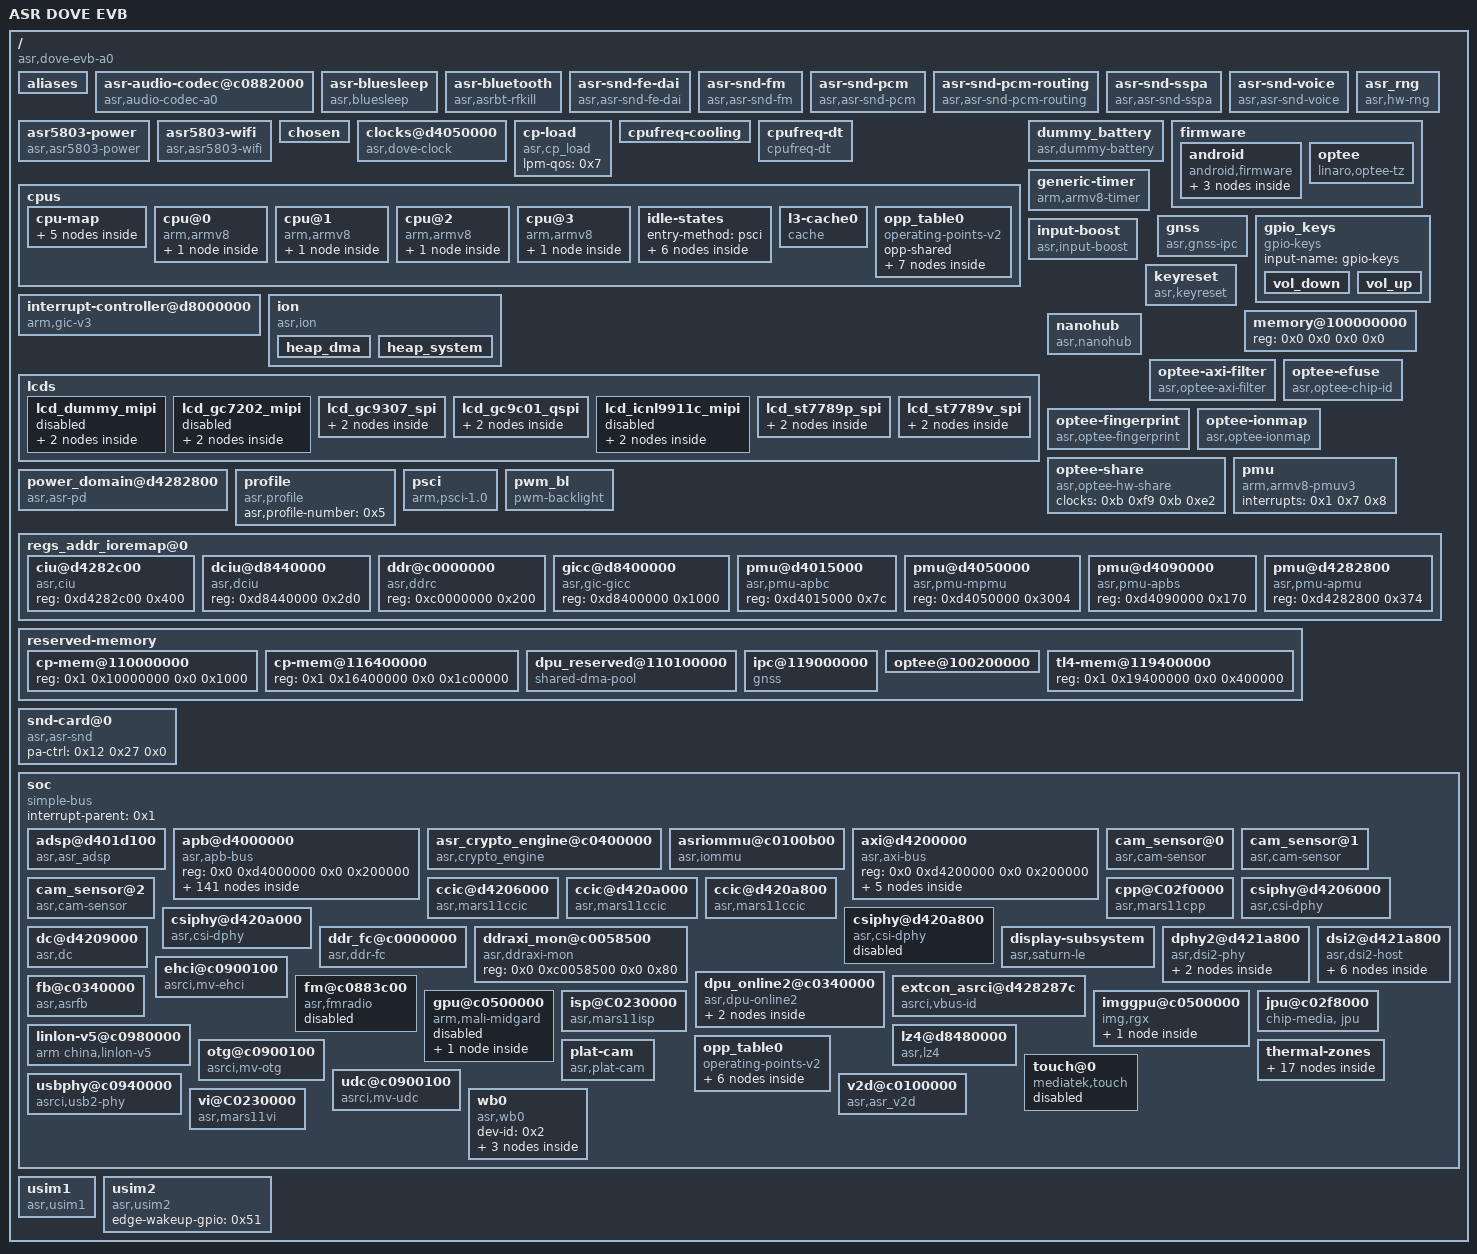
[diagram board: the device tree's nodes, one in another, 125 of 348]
/dts-v1/;

/ {
	#address-cells = <0x2>;
	#size-cells = <0x2>;
	board_id = <0x10000>;
	board_rev = <0x10081>;
	compatible = "asr,dove-evb-a0", "asr,dove";
	interrupt-parent = <0x1>;
	model = "ASR DOVE EVB";

	aliases {
		i2c0 = "/soc/apb@d4000000/i2c@d4011000";
		i2c1 = "/soc/apb@d4000000/i2c@d4010800";
		i2c3 = "/soc/apb@d4000000/i2c@d4018800";
		serial0 = "/soc/apb@d4000000/uart@d4017000";
		serial1 = "/soc/apb@d4000000/uart@d4018000";
		serial2 = "/soc/apb@d4000000/uart@d4017800";
		serial3 = "/soc/apb@d4000000/uart@d4024000";
	};

	asr-audio-codec@c0882000 {
		compatible = "asr,audio-codec-a0", "syscon";
		interrupt-names = "hook_key", "jack_plug";
		interrupts = <0x0 0x6e 0x4 0x0 0x6f 0x4>;
		reg = <0x0 0xc0882000 0x0 0x21c 0x0 0xc088c000 0x0 0x100>;
		reg-names = "codec_ctrl", "aud_pmu";
		status = "ok";
	};

	asr-bluesleep {
		bluetooth-uart = <0x1>;
		bt_ext_wake = <0x12 0x7a 0x0>;
		bt_host_wake = <0x12 0x72 0x0>;
		compatible = "asr,bluesleep";
		status = "ok";
	};

	asr-bluetooth {
		compatible = "asr,asrbt-rfkill";
		status = "ok";
	};

	asr-snd-fe-dai {
		compatible = "asr,asr-snd-fe-dai";
	};

	asr-snd-fm {
		compatible = "asr,asr-snd-fm";
	};

	asr-snd-pcm {
		compatible = "asr,asr-snd-pcm";
	};

	asr-snd-pcm-routing {
		compatible = "asr,asr-snd-pcm-routing";
	};

	asr-snd-sspa {
		compatible = "asr,asr-snd-sspa";
	};

	asr-snd-voice {
		compatible = "asr,asr-snd-voice";
	};

	asr5803-power {
		bt_ldo_en_gpio = <0x73>;
		bt_wifi_reset = <0x12 0x6a 0x0>;
		compatible = "asr,asr5803-power";
		host_wake_bt_gpio = <0x7a>;
		ldo_1v2-supply = <0x30>;
		status = "ok";
		vldo11_wibpa_1v8-supply = <0x4e>;
		wifi_host_wake_wlan = <0x6e>;
		wifi_ldo_en_gpio = <0x6f>;
	};

	asr5803-wifi {
		asr,is_dcs_mode = <0x1>;
		asr,is_dcxo_mode = <0x1>;
		compatible = "asr,asr5803-wifi";
		mac-address = [00 00 00 00 00 00];
		status = "ok";
	};

	asr_rng {
		compatible = "asr,hw-rng";
		status = "ok";
	};

	chosen {
		bootargs = "earlycon clk_ignore_unused log_buf_len=1M cma=16M@0x110400000 uart_dma printk.devkmsg=on";
		stdout-path = "serial0:115200n8";
	};

	clocks@d4050000 {
		#clock-cells = <0x1>;
		asr,keep_dbgclk_on;
		booton-clks = <0x2c 0x46>;
		compatible = "asr,dove-clock";
		interrupts = <0x0 0x60 0x4>;
		phandle = <0xb>;
		reg = <0x0 0xd4050000 0x0 0x209c 0x0 0xd4282800 0x0 0x400 0x0 0xd4015000 0x0 0x1000 0x0 0xd4090000 0x0 0x1000 0x0 0xd4282c00 0x0 0x400 0x0 0xd8440000 0x0 0x98 0x0 0xc0000000 0x0 0x4280>;
		reg-names = "mpmu", "apmu", "apbc", "apbs", "ciu", "dciu", "ddrc";
	};

	cp-load {
		compatible = "asr,cp_load";
		lpm-qos = <0x7>;
		status = "okay";
	};

	cpufreq-cooling {
		status = "ok";
	};

	cpufreq-dt {
		compatible = "cpufreq-dt";
		status = "okay";
	};

	cpus {
		#address-cells = <0x2>;
		#size-cells = <0x0>;

		cpu-map {

			cluster0 {

				core0 {
					cpu = <0x2>;
				};

				core1 {
					cpu = <0x3>;
				};

				core2 {
					cpu = <0x4>;
				};

				core3 {
					cpu = <0x5>;
				};
			};
		};

		cpu@0 {
			#cooling-cells = <0x2>;
			capacity-dmips-mhz = <0x400>;
			clocks = <0xb 0xb6>;
			compatible = "arm,armv8";
			cpu-idle-states = <0x6 0x7 0x8 0x9 0xa>;
			device_type = "cpu";
			dynamic-power-coefficient = <0x78>;
			enable-method = "psci";
			next-level-cache = <0xd>;
			operating-points-v2 = <0xc>;
			phandle = <0x2>;
			reg = <0x0 0x0>;

			l2-cache {
				next-level-cache = <0xe>;
				phandle = <0xd>;
			};
		};

		cpu@1 {
			#cooling-cells = <0x2>;
			capacity-dmips-mhz = <0x400>;
			clocks = <0xb 0xb6>;
			compatible = "arm,armv8";
			cpu-idle-states = <0x6 0x7 0x8 0x9 0xa>;
			device_type = "cpu";
			dynamic-power-coefficient = <0x78>;
			enable-method = "psci";
			next-level-cache = <0xf>;
			operating-points-v2 = <0xc>;
			phandle = <0x3>;
			reg = <0x0 0x100>;

			l2-cache {
				next-level-cache = <0xe>;
				phandle = <0xf>;
			};
		};

		cpu@2 {
			#cooling-cells = <0x2>;
			capacity-dmips-mhz = <0x400>;
			clocks = <0xb 0xb6>;
			compatible = "arm,armv8";
			cpu-idle-states = <0x6 0x7 0x8 0x9 0xa>;
			device_type = "cpu";
			dynamic-power-coefficient = <0x78>;
			enable-method = "psci";
			next-level-cache = <0x10>;
			operating-points-v2 = <0xc>;
			phandle = <0x4>;
			reg = <0x0 0x200>;

			l2-cache {
				next-level-cache = <0xe>;
				phandle = <0x10>;
			};
		};

		cpu@3 {
			#cooling-cells = <0x2>;
			capacity-dmips-mhz = <0x400>;
			clocks = <0xb 0xb6>;
			compatible = "arm,armv8";
			cpu-idle-states = <0x6 0x7 0x8 0x9 0xa>;
			device_type = "cpu";
			dynamic-power-coefficient = <0x78>;
			enable-method = "psci";
			next-level-cache = <0x11>;
			operating-points-v2 = <0xc>;
			phandle = <0x5>;
			reg = <0x0 0x300>;

			l2-cache {
				next-level-cache = <0xe>;
				phandle = <0x11>;
			};
		};

		idle-states {
			entry-method = "psci";

			chip-d1 {
				arm,psci-suspend-param = <0x2010455>;
				compatible = "arm,idle-state";
				entry-latency-us = <0x1f4>;
				exit-latency-us = <0x1f4>;
				local-timer-stop;
				min-residency-us = <0x7d0>;
				phandle = <0x9>;
				wakeup-latency-us = <0x3e8>;
			};

			chip-d1p {
				arm,psci-suspend-param = <0x2010355>;
				compatible = "arm,idle-state";
				entry-latency-us = <0x12c>;
				exit-latency-us = <0x12c>;
				local-timer-stop;
				min-residency-us = <0x4b0>;
				phandle = <0x8>;
				wakeup-latency-us = <0x258>;
			};

			chip-d2 {
				arm,psci-suspend-param = <0x2010555>;
				compatible = "arm,idle-state";
				entry-latency-us = <0x3e8>;
				exit-latency-us = <0x3e8>;
				local-timer-stop;
				min-residency-us = <0xfa0>;
				phandle = <0xa>;
				wakeup-latency-us = <0x7d0>;
			};

			cluster-mp2 {
				arm,psci-suspend-param = <0x1010055>;
				compatible = "arm,idle-state";
				entry-latency-us = <0xf0>;
				exit-latency-us = <0xf0>;
				local-timer-stop;
				min-residency-us = <0x3c0>;
				phandle = <0x7>;
				wakeup-latency-us = <0x1e0>;
			};

			cpu-c1 {
				arm,psci-suspend-param = <0x2>;
				compatible = "arm,idle-state";
				entry-latency-us = <0x19>;
				exit-latency-us = <0x19>;
				min-residency-us = <0x64>;
			};

			cpu-c2 {
				arm,psci-suspend-param = <0x10005>;
				compatible = "arm,idle-state";
				entry-latency-us = <0x5a>;
				exit-latency-us = <0x5a>;
				local-timer-stop;
				min-residency-us = <0x168>;
				phandle = <0x6>;
			};
		};

		l3-cache0 {
			compatible = "cache";
			phandle = <0xe>;
		};

		opp_table0 {
			compatible = "operating-points-v2";
			opp-shared;
			phandle = <0xc>;

			opp1000000000 {
				clock-latency-ns = <0x30d40>;
				opp-hz = <0x0 0x3b9aca00>;
				opp-microvolt = <0x16e360>;
			};

			opp1228000000 {
				clock-latency-ns = <0x30d40>;
				opp-hz = <0x0 0x4931cb00>;
				opp-microvolt = <0x16e360>;
			};

			opp1500000000 {
				clock-latency-ns = <0x30d40>;
				opp-hz = <0x0 0x59682f00>;
				opp-microvolt = <0x16e360>;
			};

			opp409000000 {
				clock-latency-ns = <0x30d40>;
				opp-hz = <0x0 0x1860d840>;
				opp-microvolt = <0xf4240>;
			};

			opp491000000 {
				clock-latency-ns = <0x30d40>;
				opp-hz = <0x0 0x1d4410c0>;
				opp-microvolt = <0xf4240>;
			};

			opp614000000 {
				clock-latency-ns = <0x30d40>;
				opp-hz = <0x0 0x2498e580>;
				opp-microvolt = <0x16e360>;
			};

			opp819000000 {
				clock-latency-ns = <0x30d40>;
				opp-hz = <0x0 0x30d0f2c0>;
				opp-microvolt = <0x16e360>;
			};
		};
	};

	dummy_battery {
		compatible = "asr,dummy-battery";
		status = "okay";
	};

	firmware {

		android {
			compatible = "android,firmware";

			fstab {
				compatible = "android,fstab";

				system {
					compatible = "android,system";
					dev = "/dev/block/platform/soc/d4200000.axi/d4281000.sdh/by-name/system";
					fsmgr_flags = "wait";
					mnt_flags = "ro,barrier=1";
					type = "ext4";
				};

				vendor {
					compatible = "android,vendor";
					dev = "/dev/block/platform/soc/d4200000.axi/d4281000.sdh/by-name/vendor";
					fsmgr_flags = "wait";
					mnt_flags = "ro,barrier=1";
					type = "ext4";
				};
			};
		};

		optee {
			compatible = "linaro,optee-tz";
			interrupts = <0x0 0x7d 0x4>;
			method = "smc";
		};
	};

	generic-timer {
		arm,no-tick-in-suspend;
		clock-frequency = <0x18cba80>;
		compatible = "arm,armv8-timer";
		interrupts = <0x1 0xd 0x8 0x1 0xe 0x8 0x1 0xb 0x8 0x1 0xa 0x8>;
	};

	gnss {
		clock-names = "ap2gnss_clk";
		clocks = <0xb 0x12a>;
		compatible = "asr,gnss-ipc";
		interrupt-names = "gnss_ipc", "gnss_wdt", "gnss_hostwake";
		interrupts = <0x0 0x32 0x4 0x0 0x65 0x4 0x0 0x66 0x4>;
		lna_1v8-supply = <0x49>;
		memory-region = <0x47>;
		reg = <0x0 0xd4282800 0x0 0x3bc 0x0 0xd6200000 0x0 0xfc 0x0 0xd401d200 0x0 0x14 0x0 0xd4015000 0x0 0x9c 0x0 0xd6000000 0x0 0x80000>;
		rf_1v2-supply = <0x30>;
		status = "ok";
		tcxo_1v8-supply = <0x48>;
	};

	gpio_keys {
		compatible = "gpio-keys";
		input-name = "gpio-keys";
		status = "ok";

		vol_down {
			debounce-interval = <0xf>;
			gpios = <0x12 0x3a 0x1>;
			label = "volume_down";
			linux,code = <0x72>;
			linux,input-type = <0x1>;
		};

		vol_up {
			debounce-interval = <0xf>;
			gpios = <0x12 0x39 0x1>;
			label = "volume_up";
			linux,code = <0x73>;
			linux,input-type = <0x1>;
		};
	};

	input-boost {
		compatible = "asr,input-boost";
		status = "okay";
	};

	interrupt-controller@d8000000 {
		#address-cells = <0x2>;
		#interrupt-cells = <0x3>;
		#size-cells = <0x2>;
		compatible = "arm,gic-v3";
		interrupt-controller;
		interrupts = <0x1 0x9 0x8>;
		phandle = <0x1>;
		reg = <0x0 0xd8000000 0x0 0x200000 0x0 0xd8080000 0x0 0x200000>;
	};

	ion {
		compatible = "asr,ion";

		heap_dma {
			heap-id = <0x4>;
			heap-name = "dma";
			heap-type = "ion_dma";
		};

		heap_system {
			heap-id = <0x0>;
			heap-name = "system";
			heap-type = "ion_system";
		};
	};

	keyreset {
		compatible = "asr,keyreset";
		keyreset-need-panic;
		keys-down = <0x74 0x73 0x72>;
		status = "okay";
	};

	lcds {
		status = "ok";

		lcd_dummy_mipi {
			burst-mode = <0x2>;
			dsi-color-format = "rgb888";
			dsi-lane-number = <0x4>;
			dsi-work-mode = <0x1>;
			eotp-enable = <0x0>;
			esd-check-enable = <0x0>;
			fps = <0x3c>;
			hbp = <0x64>;
			height = <0x640>;
			height-mm = <0x7e>;
			hfp = <0x63>;
			hsync = <0x4>;
			lane-number = <0x4>;
			phy-bit-clock = <0xde698>;
			phy-escape-clock = <0xcb20>;
			phy-freq = <0x98580>;
			rgb-mode = <0x3>;
			split-enable = <0x0>;
			status = "disabled";
			use-dcs-write;
			vbp = <0x1c>;
			vfp = <0x8c>;
			vsync = <0x6>;
			width = <0x2d0>;
			width-mm = <0x48>;
			work-mode = <0x0>;

			display-timings {

				timing0 {
					clock-frequency = <0x5dc0000>;
					hactive = <0x2d0>;
					hback-porch = <0x64>;
					hfront-porch = <0x63>;
					hsync-active = <0x1>;
					hsync-len = <0x4>;
					vactive = <0x640>;
					vback-porch = <0x1c>;
					vfront-porch = <0x8c>;
					vsync-active = <0x1>;
					vsync-len = <0x6>;
				};
			};
		};

		lcd_gc7202_mipi {
			backlight = <0x4a>;
			burst-mode = <0x2>;
			dsi-color-format = "rgb888";
			dsi-lane-number = <0x4>;
			dsi-work-mode = <0x1>;
			eotp-enable = <0x0>;
			esd-check-enable = <0x1>;
			esd-check-value = <0x9c>;
			esd-recovery-enable = <0x1>;
			fps = <0x3c>;
			hbp = <0x64>;
			height = <0x640>;
			height-mm = <0x7e>;
			hfp = <0x63>;
			hsync = <0x4>;
			initial-command = [39 01 00 04 ff 55 aa 66 39 01 00 02 ff 20 39 01 00 02 fb 00 39 01 00 02 ff 21 39 01 00 02 fb 00 39 01 00 02 ff 22 39 01 00 02 fb 00 39 01 00 02 ff 23 39 01 00 02 fb 00 39 01 00 02 ff 24 39 01 00 02 fb 00 39 01 00 02 ff 26 39 01 00 02 fb 00 39 01 00 02 ff 27 39 01 00 02 fb 00 39 01 00 02 ff a3 39 01 00 02 fb 00 39 01 00 02 ff b3 39 01 00 02 fb 00 39 01 00 02 ff c3 39 01 00 02 fb 00 39 01 00 02 ff 22 39 01 00 02 e4 01 39 01 00 02 01 06 39 01 00 02 02 40 39 01 00 02 25 08 39 01 00 02 26 00 39 01 00 02 2e 6f 39 01 00 02 2f 00 39 01 00 02 36 09 39 01 00 02 37 00 39 01 00 02 3f 6f 39 01 00 02 40 00 39 01 00 02 0e 33 39 01 00 02 dc 00 39 01 00 02 08 40 39 01 00 02 ff 21 39 01 00 02 01 25 39 01 00 02 02 05 39 01 00 02 03 1a 39 01 00 02 04 25 39 01 00 02 05 25 39 01 00 02 06 01 39 01 00 02 07 0f 39 01 00 02 08 0d 39 01 00 02 09 0b 39 01 00 02 0a 09 39 01 00 02 0b 23 39 01 00 02 0c 23 39 01 00 02 0d 25 39 01 00 02 0e 25 39 01 00 02 0f 25 39 01 00 02 10 25 39 01 00 02 11 25 39 01 00 02 12 25 39 01 00 02 13 25 39 01 00 02 14 25 39 01 00 02 15 25 39 01 00 02 16 25 39 01 00 02 17 25 39 01 00 02 18 04 39 01 00 02 19 1a 39 01 00 02 1a 25 39 01 00 02 1b 25 39 01 00 02 1c 00 39 01 00 02 1d 0e 39 01 00 02 1e 0c 39 01 00 02 1f 0a 39 01 00 02 20 08 39 01 00 02 21 23 39 01 00 02 22 23 39 01 00 02 23 25 39 01 00 02 24 25 39 01 00 02 25 25 39 01 00 02 26 25 39 01 00 02 27 25 39 01 00 02 28 25 39 01 00 02 29 25 39 01 00 02 2a 25 39 01 00 02 2b 25 39 01 00 02 2d 25 39 01 00 02 45 33 39 01 00 02 7e 03 39 01 00 02 c2 85 39 01 00 02 7f 21 39 01 00 02 8b 21 39 01 00 02 80 01 39 01 00 02 8c 1a 39 01 00 02 81 1a 39 01 00 02 8d 01 39 01 00 02 af 40 39 01 00 02 b0 40 39 01 00 02 83 04 39 01 00 02 8f 04 39 01 00 02 84 55 39 01 00 02 90 55 39 01 00 02 85 55 39 01 00 02 91 55 39 01 00 02 87 00 39 01 00 02 93 00 39 01 00 02 2e 00 39 01 00 02 88 a7 39 01 00 02 89 20 39 01 00 02 8a 33 39 01 00 02 94 a7 39 01 00 02 95 20 39 01 00 02 96 33 39 01 00 02 46 53 39 01 00 02 4c 53 39 01 00 02 5e 41 39 01 00 02 64 41 39 01 00 02 82 50 39 01 00 02 8e 50 39 01 00 02 47 02 39 01 00 02 4d 01 39 01 00 02 48 01 39 01 00 02 4e 02 39 01 00 02 5f 21 39 01 00 02 65 22 39 01 00 02 60 22 39 01 00 02 66 21 39 01 00 02 76 40 39 01 00 02 77 40 39 01 00 02 7a 44 39 01 00 02 7b 44 39 01 00 02 49 55 39 01 00 02 4a 55 39 01 00 02 4f 55 39 01 00 02 50 55 39 01 00 02 61 55 39 01 00 02 62 55 39 01 00 02 67 55 39 01 00 02 68 55 39 01 00 02 c6 56 39 01 00 02 d1 13 39 01 00 02 ff b3 39 01 00 02 4a 00 39 01 00 02 7d 28 39 01 00 02 5b 00 39 01 00 02 48 23 39 01 00 02 7c 88 39 01 00 02 3e 03 39 01 00 02 3f 7f 39 01 00 02 5e 10 39 01 00 02 58 84 39 01 00 02 ff 20 39 01 00 02 29 01 39 01 00 02 2d 1f 39 01 00 02 02 27 39 01 00 02 03 27 39 01 00 02 04 45 39 01 00 02 05 45 39 01 00 02 0a 1b 39 01 00 02 0b 1b 39 01 00 02 0c 4b 39 01 00 02 0d 4b 39 01 00 02 1c 28 39 01 00 02 1d 28 39 01 00 02 77 74 39 01 00 02 78 74 39 01 00 02 a5 00 39 01 00 02 a6 ff 39 01 00 02 a9 00 39 01 00 02 aa ff 39 01 00 02 ad 00 39 01 00 02 ae ff 39 01 00 02 b1 00 39 01 00 02 b2 ff 39 01 00 02 c3 00 39 01 00 02 c4 5f 39 01 00 02 c5 00 39 01 00 02 c6 5f 39 01 00 02 b3 00 39 01 00 02 b4 20 39 01 00 02 b5 00 39 01 00 02 b6 dc 39 01 00 02 c7 00 39 01 00 02 c8 93 39 01 00 02 c9 00 39 01 00 02 ca 93 39 01 00 02 b7 00 39 01 00 02 b8 20 39 01 00 02 b9 01 39 01 00 02 ba 90 39 01 00 02 cb 00 39 01 00 02 cc 90 39 01 00 02 bb 00 39 01 00 02 bc 16 39 01 00 02 bd 00 39 01 00 02 be 12 39 01 00 02 d5 0e 39 01 00 02 7e 01 39 01 00 02 7f 00 39 01 00 02 80 01 39 01 00 02 81 00 39 01 00 02 82 00 39 01 00 02 83 04 39 01 00 02 84 04 39 01 00 02 85 01 39 01 00 02 86 8b 39 01 00 02 87 01 39 01 00 02 88 8b 39 01 00 02 8a 03 39 01 00 02 8b 03 39 01 00 02 18 44 39 01 00 02 17 51 39 01 00 02 12 a2 39 01 00 02 15 4c 39 01 00 02 a3 44 39 01 00 02 a7 44 39 01 00 02 d3 03 39 01 00 02 24 99 39 01 00 02 25 06 39 01 00 02 ff 23 39 01 00 11 01 00 00 00 14 00 53 00 7e 00 95 00 b0 00 be 00 d0 39 01 00 11 02 00 e0 01 0e 01 32 01 61 01 80 01 b4 01 dd 01 de 39 01 00 11 03 02 0a 02 44 02 6b 02 a0 02 c4 02 f6 03 06 03 18 39 01 00 0d 04 03 2b 03 44 03 62 03 88 03 c5 03 ff 39 01 00 11 05 00 00 00 14 00 53 00 7e 00 95 00 b0 00 be 00 d0 39 01 00 11 06 00 e0 01 0e 01 32 01 61 01 80 01 b4 01 dd 01 de 39 01 00 11 07 02 0a 02 44 02 6b 02 a0 02 c4 02 f6 03 06 03 18 39 01 00 0d 08 03 2b 03 44 03 62 03 88 03 c5 03 ff 39 01 00 11 09 00 00 00 14 00 53 00 7e 00 95 00 b0 00 be 00 d0 39 01 00 11 0a 00 e0 01 0e 01 32 01 61 01 80 01 b4 01 dd 01 de 39 01 00 11 0b 02 0a 02 44 02 6b 02 a0 02 c4 02 f6 03 06 03 18 39 01 00 0d 0c 03 2b 03 44 03 62 03 88 03 c5 03 ff 39 01 00 11 0d 00 00 00 14 00 53 00 7e 00 95 00 b0 00 be 00 d0 39 01 00 11 0e 00 e0 01 0e 01 32 01 61 01 80 01 b4 01 dd 01 de 39 01 00 11 0f 02 0a 02 44 02 6b 02 a0 02 c4 02 f6 03 06 03 18 39 01 00 0d 10 03 2b 03 44 03 62 03 88 03 c5 03 ff 39 01 00 11 11 00 00 00 14 00 53 00 7e 00 95 00 b0 00 be 00 d0 39 01 00 11 12 00 e0 01 0e 01 32 01 61 01 80 01 b4 01 dd 01 de 39 01 00 11 13 02 0a 02 44 02 6b 02 a0 02 c4 02 f6 03 06 03 18 39 01 00 0d 14 03 2b 03 44 03 62 03 88 03 c5 03 ff 39 01 00 11 15 00 00 00 14 00 53 00 7e 00 95 00 b0 00 be 00 d0 39 01 00 11 16 00 e0 01 0e 01 32 01 61 01 80 01 b4 01 dd 01 de 39 01 00 11 17 02 0a 02 44 02 6b 02 a0 02 c4 02 f6 03 06 03 18 39 01 00 0d 18 03 2b 03 44 03 62 03 88 03 c5 03 ff 39 01 00 02 b9 31 39 01 00 02 b8 b7 39 01 00 02 35 16 39 01 00 02 36 0c 39 01 00 02 30 00 39 01 00 11 1f 0a 00 20 00 44 00 70 00 a8 00 e6 00 0a 00 20 00 39 01 00 09 20 44 00 70 00 a8 00 ff 00 39 01 00 11 21 a7 00 b2 00 c0 00 cd 00 da 00 f3 00 d4 00 e4 00 39 01 00 09 22 ec 00 f1 00 f1 00 ff 00 39 01 00 11 23 00 00 00 00 00 00 00 00 00 00 00 00 00 00 00 00 39 01 00 09 24 00 00 00 00 00 00 00 00 39 01 00 02 ff 20 39 01 00 02 50 00 39 01 00 02 51 22 39 01 00 02 ff 26 39 01 00 05 1d 0c 00 00 00 39 01 00 02 ff a3 39 01 00 02 fa 01 39 01 00 02 35 00 39 01 00 02 45 10 39 01 00 02 05 05 39 01 00 02 2b fb 39 01 00 02 ff 10 39 01 00 02 36 08 39 01 00 02 69 00 39 01 00 02 35 00 39 01 00 02 ff b3 39 01 78 02 51 11 39 01 00 02 ff 10 39 01 78 02 11 00 39 01 14 02 29 00];
			lane-number = <0x4>;
			phy-bit-clock = <0xde698>;
			phy-escape-clock = <0xcb20>;
			phy-freq = <0x98580>;
			read-id-command = [37 01 00 01 01 14 01 00 01 04];
			rgb-mode = <0x3>;
			sleep-in-command = [39 01 00 04 ff 55 aa 66 39 01 00 02 ff 20 39 01 00 02 4a 01 39 01 00 02 48 10 39 01 00 02 49 00 39 01 00 02 ff 21 39 01 00 02 d1 00 39 01 00 02 ff 10 05 01 14 01 28 39 01 00 02 ff b3 39 01 32 02 61 be 39 01 00 02 ff 10 05 01 78 01 10 39 01 00 02 ff b3 39 01 32 02 61 00 39 01 00 04 ff 55 aa 66 39 01 00 02 ff 26 39 01 00 02 fb 00 39 01 00 05 1d a2 aa aa 0a 39 01 00 02 ff 10 39 01 00 02 fb 00 39 01 0a 02 4f 01];
			sleep-out-command = [05 01 78 01 11 05 01 14 01 29];
			split-enable = <0x0>;
			status = "disabled";
			use-dcs-write;
			vbp = <0x1c>;
			vfp = <0x8c>;
			vsync = <0x6>;
			width = <0x2d0>;
			width-mm = <0x48>;
			work-mode = <0x0>;

			display-timings {

				timing0 {
					clock-frequency = <0x5dc0000>;
					hactive = <0x2d0>;
					hback-porch = <0x64>;
					hfront-porch = <0x63>;
					hsync-active = <0x1>;
					hsync-len = <0x4>;
					vactive = <0x640>;
					vback-porch = <0x1c>;
					vfront-porch = <0x8c>;
					vsync-active = <0x1>;
					vsync-len = <0x6>;
				};
			};
		};

		lcd_gc9307_spi {
			bg-color = <0xff>;
			cmd-initial-0 = [00 01 fe 00 00 01 ef 00 00 01 36 01 48 00 01 3a 01 05 00 01 86 01 98 00 01 89 01 03 00 01 8b 01 80 00 01 8d 01 22 00 01 8e 01 0f 00 01 e8 02 10 40 00 01 ff 01 62 00 01 99 01 3e 00 01 9d 01 4b 00 01 c3 01 34 00 01 c4 01 34 00 01 c9 01 2a 00 01 f0 06 87 08 09 08 06 29 00 01 f2 06 87 08 09 08 06 29 00 01 f1 06 c0 89 6a 3c fe 3f 00 01 f3 06 c0 89 6a 3c fe 3f 00 01 35 01 00 00 01 44 02 00 0a 78 01 11 00 00 01 29 00 14 01 2c 00];
			cmd-initial-1 = [00 01 fe 00 00 01 ef 00 00 01 36 01 48 00 01 3a 01 05 00 01 86 01 98 00 01 89 01 03 00 01 8b 01 80 00 01 8d 01 22 00 01 8e 01 0f 00 01 e8 02 20 40 00 01 ff 01 62 00 01 99 01 3e 00 01 9d 01 4b 00 01 c3 01 34 00 01 c4 01 34 00 01 c9 01 2a 00 01 f0 06 87 08 09 08 06 29 00 01 f2 06 87 08 09 08 06 29 00 01 f1 06 c0 89 6a 3c fe 3f 00 01 f3 06 c0 89 6a 3c fe 3f 00 01 35 01 00 00 01 44 02 00 1a 78 01 11 00 00 01 29 00 14 01 2c 00];
			cmd-initial-2 = [00 01 fe 00 00 01 ef 00 00 01 36 01 48 00 01 35 01 00 00 01 3a 01 05 00 01 86 01 98 00 01 89 01 13 00 01 8b 01 80 00 01 8d 01 33 00 01 8e 01 0f 00 01 ec 03 33 07 af 00 01 c9 01 05 00 01 e8 02 13 17 00 01 c3 01 10 00 01 c4 01 10 00 01 ff 01 62 00 01 99 01 3e 00 01 9d 01 4b 00 01 98 01 3e 00 01 9c 01 4b 00 01 f0 06 c7 08 08 08 05 2e 00 01 f2 06 c7 08 08 08 05 2e 00 01 f1 06 45 8f 6f 33 36 4f 00 01 f3 06 45 8f 6f 33 36 4f 00 01 44 02 00 0a 78 01 11 00 00 01 29 00 14 01 2c 00];
			cmd-initial-3 = [00 01 fe 00 00 01 ef 00 00 01 36 01 48 00 01 35 01 00 00 01 3a 01 05 00 01 86 01 98 00 01 89 01 33 00 01 8b 01 80 00 01 8d 01 33 00 01 8e 01 0f 00 01 ec 03 33 0c d1 00 01 c9 01 16 00 01 e8 02 12 00 00 01 c3 01 14 00 01 c4 01 08 00 01 ff 01 62 00 01 99 01 3e 00 01 9d 01 4b 00 01 98 01 3e 00 01 9c 01 4b 00 01 f0 06 c3 05 08 07 04 26 00 01 f2 06 c3 05 08 07 04 26 00 01 f1 06 3f 7f 6f 35 36 4f 00 01 f3 06 3f 7f 6f 35 36 4f 00 01 44 02 00 0a 78 01 11 00 00 01 29 00 14 01 2c 00];
			cmd-initial-4 = [00 01 fe 00 00 01 ef 00 00 01 36 01 48 00 01 3a 01 05 00 01 35 01 00 00 01 86 01 98 00 01 89 01 13 00 01 8b 01 80 00 01 8d 01 33 00 01 8e 01 0f 00 01 ec 03 33 07 af 00 01 c9 01 05 00 01 e8 02 13 17 00 01 c3 01 10 00 01 c4 01 10 00 01 ff 01 62 00 01 99 01 3e 00 01 9d 01 4b 00 01 98 01 3e 00 01 9c 01 4b 00 01 f0 06 c7 08 08 08 05 2e 00 01 f1 06 45 8f 6f 33 36 4f 00 01 f2 06 c7 08 08 08 05 2e 00 01 f3 06 45 8f 6f 33 36 4f 00 01 44 02 00 0a 78 01 11 00 00 01 29 00 00 01 2c 00];
			cmd-initial-5 = [00 01 fe 00 00 01 ef 00 00 01 36 01 48 00 01 3a 01 05 00 01 86 01 98 00 01 89 01 03 00 01 8b 01 80 00 01 8d 01 22 00 01 8e 01 0f 00 01 e8 02 12 00 00 01 c3 01 47 00 01 c4 01 28 00 01 c9 01 08 00 01 ff 01 62 00 01 99 01 3e 00 01 9d 01 4b 00 01 f0 06 07 0b 0c 0a 06 31 00 01 f2 06 07 07 04 06 06 21 00 01 f1 06 4a 78 76 33 2f af 00 01 f3 06 38 74 72 22 28 6f 00 01 35 01 00 00 01 44 02 00 0a 00 01 11 00 00 01 29 00 00 01 2c 00];
			cmd-initial-6 = [00 01 fe 00 00 01 ef 00 00 01 36 01 48 00 01 3a 01 05 00 01 86 01 98 00 01 89 01 33 00 01 8b 01 80 00 01 8d 01 33 00 01 8e 01 0f 00 01 ec 03 33 0c d1 00 01 c9 01 16 00 01 e8 02 13 17 00 01 c3 01 22 00 01 c4 01 16 00 01 ff 01 62 00 01 99 01 3e 00 01 9d 01 4b 00 01 98 01 3e 00 01 9c 01 4b 00 01 f0 06 c3 05 08 07 04 26 00 01 f2 06 c3 05 08 07 04 26 00 01 f1 06 3f 7f 6f 35 36 4f 00 01 f3 06 3f 7f 6f 35 36 4f 00 01 35 01 00 00 01 44 02 00 0a 78 01 11 00 00 01 29 00 14 01 2c 00];
			cmd-initial-7 = [00 01 fe 00 00 01 ef 00 00 01 36 01 48 00 01 3a 01 05 00 01 86 01 98 00 01 89 01 33 00 01 8b 01 80 00 01 8d 01 33 00 01 8e 01 0f 00 01 ec 03 33 0c d1 00 01 c9 01 16 00 01 e8 02 13 17 00 01 c3 01 22 00 01 c4 01 16 00 01 ff 01 62 00 01 99 01 3e 00 01 9d 01 4b 00 01 98 01 3e 00 01 9c 01 4b 00 01 f0 06 c3 05 08 07 04 26 00 01 f2 06 c3 05 08 07 04 26 00 01 f1 06 3f 7f 6f 35 36 4f 00 01 f3 06 3f 7f 6f 35 36 4f 00 01 35 01 00 00 01 44 02 00 0a 78 01 11 00 00 01 29 00 14 01 2c 00];
			cmd-read-id = [00 01 da 01 00 00 01 db 01 93 00 01 dc 01 07 00 01 04 03 07 93 00];
			cmd-set-window-240x240 = <0x12a04 0xef 0x12b04 0xef 0x12c00>;
			cmd-set-window-240x280 = <0x12a04 0xef 0x12b04 0x13012b 0x12c00>;
			cmd-set-window-240x284 = <0x12a04 0xef 0x12b04 0x11b 0x12c00>;
			cmd-set-window-240x296 = <0x12a04 0xef 0x12b04 0x127 0x12c00>;
			cmd-set-window-240x320 = <0x12a04 0xef 0x12b04 0x13f 0x12c00>;
			cmd-sleep-in = <0x14012800 0x78011000>;
			cmd-sleep-out = <0x78011100 0x78012900>;
			custom-cmd-set-window = <0x0>;
			data-lane-number = <0x1>;
			device-id = <0x0>;
			endian = <0x1>;
			format = "rgb565";
			frame-sync;
			height-mm = <0x7e>;
			interface-id = <0x1>;
			line-number = <0x4>;
			mclk-freq = <0x124f8000>;
			non-block;
			reset-sequence = <0x140178>;
			sample-edge = <0x0>;
			spi-rclk-freq = <0x177000>;
			spi-wclk-freq = <0x3197500>;
			te-en = <0x1>;
			te-polarity = <0x0>;
			width-mm = <0x48>;

			display-timings {

				timing0 {
					clock-frequency = <0x4a6214>;
					hactive = <0xf0>;
					hback-porch = <0x64>;
					hfront-porch = <0x63>;
					hsync-active = <0x1>;
					hsync-len = <0x4>;
					vactive = <0xf0>;
					vback-porch = <0x8>;
					vfront-porch = <0x8>;
					vsync-active = <0x1>;
					vsync-len = <0x6>;
				};
			};
		};

		lcd_gc9c01_qspi {
			bg-color = <0xff>;
			cmd-initial = [00 04 02 00 fe 00 00 00 04 02 00 ef 00 00 00 04 02 00 80 00 01 11 00 04 02 00 81 00 01 70 00 04 02 00 82 00 01 09 00 04 02 00 83 00 01 03 00 04 02 00 84 00 01 20 00 04 02 00 89 00 01 10 00 04 02 00 8a 00 01 4f 00 04 02 00 8b 00 01 08 00 04 02 00 8c 00 01 59 00 04 02 00 8d 00 01 51 00 04 02 00 36 00 01 00 00 04 02 00 3a 00 01 05 00 04 02 00 ec 00 01 77 00 04 02 00 74 00 06 01 80 00 00 00 00 00 04 02 00 98 00 01 3e 00 04 02 00 99 00 01 3e 00 04 02 00 c3 00 01 3a 00 04 02 00 c4 00 01 16 00 04 02 00 a1 00 02 01 04 00 04 02 00 a2 00 02 01 04 00 04 02 00 cb 00 01 02 00 04 02 00 7c 00 02 b6 26 00 04 02 00 ac 00 01 24 00 04 02 00 f6 00 01 80 00 04 02 00 b5 00 02 09 09 00 04 02 00 60 00 04 38 0b 5b 56 00 04 02 00 63 00 04 3a e0 5b 56 00 04 02 00 64 00 06 38 0d 72 dd 5b 56 00 04 02 00 66 00 06 38 11 72 e1 5b 56 00 04 02 00 68 00 07 3b 08 08 00 08 29 5b 00 04 02 00 6e 00 20 00 00 00 07 01 13 11 0b 09 16 15 1d 1e 00 00 00 00 00 00 1e 1d 15 16 0a 0c 12 14 02 08 00 00 00 00 04 02 00 be 00 01 11 00 04 02 00 6c 00 07 cc 0c cc 84 cc 04 50 00 04 02 00 7d 00 01 72 00 04 02 00 7e 00 01 38 00 04 02 00 70 00 0a 02 03 09 05 0c 06 09 05 0c 06 00 04 02 00 90 00 04 06 06 05 06 00 04 02 00 93 00 03 45 ff 00 00 04 02 00 f0 00 06 46 0b 0f 0a 10 3f 00 04 02 00 f1 00 06 52 9a 4f 36 37 ff 00 04 02 00 f2 00 06 46 0b 0f 0a 10 3f 00 04 02 00 f3 00 06 52 9a 4f 36 37 ff 00 04 02 00 35 00 01 00 00 04 02 00 44 00 02 00 25 00 04 02 00 b4 00 02 0a 50 00 04 02 00 fb 00 02 00 00 78 04 02 00 11 00 00 14 04 02 00 29 00 00];
			cmd-set-window = [00 04 02 00 2a 00 04 00 00 01 67 00 04 02 00 2b 00 04 00 00 01 67];
			cmd-sleep-in = [78 04 02 00 28 00 00 96 04 02 00 10 00 00];
			cmd-sleep-out = [78 04 02 00 11 00 00 64 04 02 00 29 00 00];
			cmd-start = [00 04 32 00 2c 00 00];
			data-lane-number = <0x1>;
			device-id = <0x0>;
			endian = <0x1>;
			format = "rgb565";
			frame-sync;
			height-mm = <0x7e>;
			interface-id = <0x1>;
			line-number = <0x4>;
			mclk-freq = <0x124f8000>;
			qspi;
			reset-sequence = [01 78 00 64 01 78];
			sample-edge = <0x0>;
			spi-rclk-freq = <0x177000>;
			spi-wclk-freq = <0x30d4000>;
			te-en = <0x0>;
			te-polarity = <0x0>;
			width-mm = <0x48>;

			display-timings {

				timing0 {
					clock-frequency = <0x3197500>;
					hactive = <0x168>;
					hback-porch = <0x64>;
					hfront-porch = <0x63>;
					hsync-active = <0x1>;
					hsync-len = <0x4>;
					vactive = <0x168>;
					vback-porch = <0x8>;
					vfront-porch = <0x8>;
					vsync-active = <0x1>;
					vsync-len = <0x6>;
				};
			};
		};

		lcd_icnl9911c_mipi {
			backlight = <0x4a>;
			burst-mode = <0x2>;
			dsi-color-format = "rgb888";
			dsi-lane-number = <0x4>;
			dsi-work-mode = <0x1>;
			eotp-enable = <0x0>;
			esd-check-enable = <0x1>;
			esd-check-value = <0x1c>;
			esd-recovery-enable = <0x1>;
			fps = <0x3c>;
			hbp = <0x60>;
			height = <0x640>;
			height-mm = <0x7e>;
			hfp = <0x61>;
			hsync = <0x4>;
			initial-command = [39 01 00 04 df 93 83 16 39 01 00 02 de 00 39 01 00 13 b3 10 80 85 00 ff ff 00 00 00 00 64 64 3c 3c 33 11 50 50 39 01 00 06 b2 01 23 60 88 24 39 01 00 04 b6 0c 99 ae 39 01 00 04 b9 3c 33 35 39 01 00 08 bb 0c 31 43 64 3c 20 20 39 01 00 03 bd 00 6c 39 01 00 06 c0 00 d5 00 d5 00 39 01 00 2b cb 5e 4d 40 2f 22 1e 11 19 07 27 2b 30 52 42 4d 41 3e 33 23 17 02 5e 4d 40 2f 22 1e 11 19 07 27 2b 30 52 42 4d 41 3e 33 23 17 02 39 01 00 02 cc 33 39 01 00 03 cd 10 10 39 01 00 05 bf 50 32 33 c3 39 01 00 0e c3 13 00 06 16 9b 00 9d 08 16 04 18 08 16 39 01 00 0b c5 30 20 87 00 00 00 00 38 00 11 39 01 00 05 c6 00 b6 d2 14 39 01 00 11 ce 01 00 00 00 00 00 3c 3c 3c 3c 3c 3c 3c 3c 3c 3c 39 01 00 11 cf 00 00 00 00 00 00 c0 c0 c0 c0 c0 c0 c0 c0 c0 c0 39 01 00 1e d0 00 1f 1f 1f 1f 1f 1e 1f 17 18 04 06 08 0a 00 10 1f 1f 1f 1f 1f 1f 1f 00 00 00 03 c0 00 39 01 00 1e d1 00 1f 1f 1f 1f 1f 1e 1f 17 18 05 07 09 0b 01 11 1f 1f 1f 1f 1f 1f 1f 00 00 00 03 c0 00 39 01 00 1e d2 00 1f 1f 1f 1f 1f 1f 1e 17 18 0b 09 07 05 11 01 1f 1f 1f 1f 1f 1f 1f 00 00 00 03 c0 00 39 01 00 1e d3 00 1f 1f 1f 1f 1f 1f 1e 17 18 0a 08 06 04 10 00 1f 1f 1f 1f 1f 1f 1f 00 00 00 03 c0 00 39 01 00 3f d4 10 00 00 10 00 0d 00 00 00 00 00 03 04 00 10 a6 54 00 04 03 03 00 01 00 04 01 01 11 60 03 00 05 01 01 00 00 04 00 0a 06 61 00 0f 00 00 00 00 00 00 00 00 00 00 00 00 00 00 00 00 81 03 d4 39 01 00 1c d5 03 10 03 00 01 00 00 00 00 43 00 00 00 07 32 5a 00 4a 3b 00 00 1e 02 73 00 12 00 39 01 00 14 d7 00 69 79 69 79 69 79 69 79 69 79 2f 79 69 79 69 79 69 79 39 01 00 02 de 01 39 01 00 02 b5 6f 39 01 00 03 c5 22 12 39 01 00 08 c6 3f 0c 00 00 01 e0 78 39 01 00 02 de 02 39 01 00 06 b3 20 a0 ea 5f 4b 39 01 00 09 b7 44 00 88 00 03 00 6e 10 39 01 00 02 bd 14 39 01 00 09 c1 00 40 20 00 14 14 14 14 39 01 00 08 c2 42 70 01 01 e0 73 f8 39 01 00 07 c3 20 fb 00 a0 20 62 39 01 00 0b e5 00 e6 e5 02 27 42 27 42 09 00 39 01 00 04 e6 10 10 bd 39 01 00 04 ec 01 7f 22 39 01 00 02 de 03 39 01 00 02 d1 00 39 01 00 02 de 00 39 01 1e 02 35 00 39 01 78 02 11 00 39 01 78 02 29 00];
			lane-number = <0x4>;
			phy-bit-clock = <0xde698>;
			phy-escape-clock = <0xcb20>;
			phy-freq = <0x98580>;
			read-id-command = [37 01 00 01 01 14 01 00 01 04];
			rgb-mode = <0x3>;
			sleep-in-command = [39 01 78 01 28 39 01 78 01 10];
			sleep-out-command = [05 01 78 01 11 05 01 14 01 29];
			split-enable = <0x0>;
			status = "disabled";
			use-dcs-write;
			vbp = <0x20>;
			vfp = <0x96>;
			vsync = <0x4>;
			width = <0x2d0>;
			width-mm = <0x48>;
			work-mode = <0x0>;

			display-timings {

				timing0 {
					clock-frequency = <0x5dc0000>;
					hactive = <0x2d0>;
					hback-porch = <0x60>;
					hfront-porch = <0x61>;
					hsync-active = <0x1>;
					hsync-len = <0x4>;
					vactive = <0x640>;
					vback-porch = <0x20>;
					vfront-porch = <0x96>;
					vsync-active = <0x1>;
					vsync-len = <0x4>;
				};
			};
		};

		lcd_st7789p_spi {
			bg-color = <0xff>;
			cmd-initial = [78 01 11 00 78 01 36 01 00 00 01 b0 02 00 d0 00 01 3a 01 05 00 01 b2 05 07 07 00 33 33 00 01 b7 01 35 00 01 bb 01 20 00 01 c0 01 2c 00 01 c2 01 01 00 01 c3 01 13 00 01 c6 01 13 00 01 d0 02 a7 a1 00 01 d0 02 a4 a1 00 01 d6 01 a1 00 01 e0 0e f0 03 08 07 06 13 2b 33 41 36 12 12 28 30 00 01 e1 0e f0 05 0a 09 08 05 2b 32 40 37 14 14 29 31 00 01 35 01 00 00 01 44 02 00 0e 00 01 21 00 00 01 29 00];
			cmd-read-id = [00 01 da 01 81 00 01 db 01 81 00 01 dc 01 b3 00 01 04 03 b3 81 81];
			cmd-set-window = <0x12a04 0xef 0x12b04 0x127 0x12c00>;
			cmd-sleep-in = <0x14012800 0x78011000>;
			cmd-sleep-out = <0x78011100 0x14012900>;
			data-lane-number = <0x1>;
			device-id = <0x0>;
			endian = <0x1>;
			format = "rgb565";
			frame-sync;
			height-mm = <0x7e>;
			interface-id = <0x1>;
			line-number = <0x4>;
			mclk-freq = <0x124f8000>;
			non-block;
			reset-sequence = <0x10105>;
			sample-edge = <0x0>;
			spi-rclk-freq = <0x177000>;
			spi-wclk-freq = <0x30d4000>;
			te-en = <0x1>;
			te-polarity = <0x0>;
			width-mm = <0x48>;

			display-timings {

				timing0 {
					clock-frequency = <0x80f958>;
					hactive = <0xf0>;
					hback-porch = <0x64>;
					hfront-porch = <0x63>;
					hsync-active = <0x1>;
					hsync-len = <0x4>;
					vactive = <0x128>;
					vback-porch = <0x8>;
					vfront-porch = <0x8>;
					vsync-active = <0x1>;
					vsync-len = <0x6>;
				};
			};
		};

		lcd_st7789v_spi {
			bg-color = <0xff>;
			cmd-initial = [78 01 11 00 78 01 36 01 00 00 01 3a 01 06 00 01 35 01 00 00 01 c7 01 00 00 01 cc 01 09 00 01 b2 05 0c 0c 00 33 33 00 01 b7 01 35 00 01 bb 01 19 00 01 c0 01 2c 00 01 c2 01 01 00 01 c3 01 12 00 01 c4 01 20 00 01 c6 01 0f 00 01 d0 02 a4 a1 00 01 e0 0e d0 03 0e 11 17 1f 4c 53 5b 1a 16 13 25 28 00 01 e1 0e d0 02 0e 11 16 1e 4a 36 56 1a 15 14 26 28 00 01 29 00];
			cmd-read-id = [00 01 da 01 85 00 01 db 01 85 00 01 dc 01 52 00 01 04 03 52 85 85];
			cmd-set-window = <0x12a04 0xef 0x12b04 0xef 0x12c00>;
			cmd-sleep-in = <0x14012800 0x78011000>;
			cmd-sleep-out = <0x78011100 0x14012900>;
			data-lane-number = <0x1>;
			device-id = <0x0>;
			endian = <0x1>;
			format = "rgb666";
			frame-sync;
			height-mm = <0x7e>;
			interface-id = <0x1>;
			line-number = <0x4>;
			mclk-freq = <0x124f8000>;
			non-block;
			reset-sequence = <0x140178>;
			sample-edge = <0x0>;
			spi-rclk-freq = <0x177000>;
			spi-wclk-freq = <0x30d4000>;
			te-en = <0x1>;
			te-polarity = <0x0>;
			width-mm = <0x48>;

			display-timings {

				timing0 {
					clock-frequency = <0x3197500>;
					hactive = <0xf0>;
					hback-porch = <0x64>;
					hfront-porch = <0x63>;
					hsync-active = <0x1>;
					hsync-len = <0x4>;
					vactive = <0xf0>;
					vback-porch = <0x8>;
					vfront-porch = <0x8>;
					vsync-active = <0x1>;
					vsync-len = <0x6>;
				};
			};
		};
	};

	memory@100000000 {
		device_type = "memory";
		reg = <0x0 0x0 0x0 0x0>;
	};

	nanohub {
		compatible = "asr,nanohub";
		gpi-count = <0x3>;
		gpi-list = <0x4a 0x4b 0x4c>;
		pinctrl-0 = <0x4c>;
		pinctrl-names = "sh_i2c";
		sensor_3v3-supply = <0x4b>;
		status = "ok";
	};

	optee-axi-filter {
		compatible = "asr,optee-axi-filter";
		status = "ok";
	};

	optee-efuse {
		compatible = "asr,optee-chip-id";
		status = "ok";
	};

	optee-fingerprint {
		compatible = "asr,optee-fingerprint";
		status = "ok";
	};

	optee-ionmap {
		compatible = "asr,optee-ionmap";
		status = "ok";
	};

	optee-share {
		clock-names = "aes", "ssp2";
		clocks = <0xb 0xf9 0xb 0xe2>;
		compatible = "asr,optee-hw-share";
		status = "ok";
	};

	pmu {
		compatible = "arm,armv8-pmuv3";
		interrupts = <0x1 0x7 0x8>;
	};

	power_domain@d4282800 {
		#power-domain-cells = <0x1>;
		asr-pd,pwr-blk-tmr = <0x10f3f0f>;
		clock-names = "vpu", "gpu", "audio", "ispfnc", "ispbus", "ispsc2ahb", "cppfnc", "ccicfnc", "dpuhclk", "dpumclk", "dpupxclk", "dpuescclk", "dpubitclk";
		clocks = <0xb 0xed 0xb 0xeb 0xb 0x10e 0xb 0xff 0xb 0xfe 0xb 0x101 0xb 0x123 0xb 0x100 0xb 0xf1 0xb 0xf2 0xb 0xf0 0xb 0xf5 0xb 0xf6>;
		compatible = "asr,asr-pd";
		phandle = <0x24>;
		reg = <0x0 0xd4282800 0x0 0x400>;
		status = "ok";
	};

	profile {
		asr,profile-number = <0x5>;
		compatible = "asr,profile";
	};

	psci {
		compatible = "arm,psci-1.0";
		cpu_off = <0x84000002>;
		cpu_on = <0xc4000003>;
		cpu_suspend = <0xc4000001>;
		method = "smc";
	};

	pwm_bl {
		brightness-levels = <0x0 0x1 0x2 0x3 0x4 0x5 0x6 0x7 0x8 0x9 0xa 0xb 0xc 0xd 0xe 0xf 0x10 0x11 0x12 0x13 0x14 0x15 0x16 0x17 0x18 0x19 0x1a 0x1b 0x1c 0x1d 0x1e 0x1f 0x20 0x21 0x22 0x23 0x24 0x25 0x26 0x27 0x28 0x29 0x2a 0x2b 0x2c 0x2d 0x2e 0x2f 0x30 0x31 0x32 0x33 0x34 0x35 0x36 0x37 0x38 0x39 0x3a 0x3b 0x3c 0x3d 0x3e 0x3f 0x40 0x41 0x42 0x43 0x44 0x45 0x46 0x47 0x48 0x49 0x4a 0x4b 0x4c 0x4d 0x4e 0x4f 0x50 0x51 0x52 0x53 0x54 0x55 0x56 0x57 0x58 0x59 0x5a 0x5b 0x5c 0x5d 0x5e 0x5f 0x60 0x61 0x62 0x63 0x64 0x65 0x66 0x67 0x68 0x69 0x6a 0x6b 0x6c 0x6d 0x6e 0x6f 0x70 0x71 0x72 0x73 0x74 0x75 0x76 0x77 0x78 0x79 0x7a 0x7b 0x7c 0x7d 0x7e 0x7f 0x80 0x81 0x82 0x83 0x84 0x85 0x86 0x87 0x88 0x89 0x8a 0x8b 0x8c 0x8d 0x8e 0x8f 0x90 0x91 0x92 0x93 0x94 0x95 0x96 0x97 0x98 0x99 0x9a 0x9b 0x9c 0x9d 0x9e 0x9f 0xa0 0xa1 0xa2 0xa3 0xa4 0xa5 0xa6 0xa7 0xa8 0xa9 0xaa 0xab 0xac 0xad 0xae 0xaf 0xb0 0xb1 0xb2 0xb3 0xb4 0xb5 0xb6 0xb7 0xb8 0xb9 0xba 0xbb 0xbc 0xbd 0xbe 0xbf 0xc0 0xc1 0xc2 0xc3 0xc4 0xc5 0xc6 0xc7 0xc8 0xc9 0xca 0xcb 0xcc 0xcd 0xce 0xcf 0xd0 0xd1 0xd2 0xd3 0xd4 0xd5 0xd6 0xd7 0xd8 0xd9 0xda 0xdb 0xdc 0xdd 0xde 0xdf 0xe0 0xe1 0xe2 0xe3 0xe4 0xe5 0xe6 0xe7 0xe8 0xe9 0xea 0xeb 0xec 0xed 0xee 0xef 0xf0 0xf1 0xf2 0xf3 0xf4 0xf5 0xf6 0xf7 0xf8 0xf9 0xfa 0xfb 0xfc 0xfd 0xfe 0xff>;
		compatible = "pwm-backlight";
		default-brightness-level = <0x80>;
		phandle = <0x4a>;
		pwms = <0x46 0x0 0x4ebc>;
		status = "ok";
	};

	regs_addr_ioremap@0 {
		#address-cells = <0x1>;
		#size-cells = <0x1>;
		ranges = <0x0 0x0 0x0 0xffffffff>;

		ciu@d4282c00 {
			compatible = "asr,ciu", "syscon";
			reg = <0xd4282c00 0x400>;
		};

		dciu@d8440000 {
			compatible = "asr,dciu", "syscon";
			reg = <0xd8440000 0x2d0>;
		};

		ddr@c0000000 {
			compatible = "asr,ddrc", "syscon";
			reg = <0xc0000000 0x200>;
		};

		gicc@d8400000 {
			compatible = "asr,gic-gicc", "syscon";
			reg = <0xd8400000 0x1000>;
		};

		pmu@d4015000 {
			compatible = "asr,pmu-apbc", "syscon";
			reg = <0xd4015000 0x7c>;
		};

		pmu@d4050000 {
			compatible = "asr,pmu-mpmu", "syscon";
			reg = <0xd4050000 0x3004>;
		};

		pmu@d4090000 {
			compatible = "asr,pmu-apbs", "syscon";
			reg = <0xd4090000 0x170>;
		};

		pmu@d4282800 {
			compatible = "asr,pmu-apmu", "syscon";
			reg = <0xd4282800 0x374>;
		};
	};

	reserved-memory {
		#address-cells = <0x2>;
		#size-cells = <0x2>;
		ranges;

		cp-mem@110000000 {
			reg = <0x1 0x10000000 0x0 0x1000>;
		};

		cp-mem@116400000 {
			reg = <0x1 0x16400000 0x0 0x1c00000>;
		};

		dpu_reserved@110100000 {
			compatible = "shared-dma-pool";
			no-map;
			phandle = <0x2d>;
			reg = <0x1 0x10100000 0x0 0x60000>;
		};

		ipc@119000000 {
			compatible = "gnss";
			no-map;
			phandle = <0x47>;
			reg = <0x1 0x19000000 0x0 0x100000>;
		};

		optee@100200000 {
			no-map;
			reg = <0x1 0x200000 0x0 0xe00000>;
		};

		tl4-mem@119400000 {
			reg = <0x1 0x19400000 0x0 0x400000>;
		};
	};

	snd-card@0 {
		compatible = "asr,asr-snd";
		pa-ctrl = <0x12 0x27 0x0>;
	};

	soc {
		#address-cells = <0x2>;
		#size-cells = <0x2>;
		compatible = "simple-bus";
		interrupt-parent = <0x1>;
		ranges;

		adsp@d401d100 {
			clock-names = "adspcore", "adspipc", "adsp_pll_d10", "adsp_pll_d100";
			clocks = <0xb 0x10e 0xb 0x10f 0xb 0x137 0xb 0x161>;
			compatible = "asr,asr_adsp";
			interrupt-names = "adsp_ipc_irq", "adsp_wakeup";
			interrupts = <0x0 0x1e 0x4 0x0 0x51 0x4>;
			reg = <0x0 0xd401d100 0x0 0x100 0x0 0xc088c000 0x0 0x1000 0x0 0xd4282800 0x0 0x400 0x0 0xc0880000 0x0 0x200 0x0 0xd4090000 0x0 0x200>;
			reg-names = "ipcreg", "bootc", "pmuap", "aud_sysctrl", "apb_spare";
			status = "okay";
		};

		apb@d4000000 {
			#address-cells = <0x1>;
			#size-cells = <0x1>;
			compatible = "asr,apb-bus", "simple-bus";
			ranges = <0x0 0x0 0x0 0xffffffff>;
			reg = <0x0 0xd4000000 0x0 0x200000>;

			acipc@d401d000 {
				binding-core-range = <0x4 0x7>;
				compatible = "mrvl,mmp-acipc";
				interrupt-names = "IPC_AP_DATAACK";
				interrupts = <0x0 0x1d 0x4>;
				reg = <0xd401d000 0x100>;
				status = "okay";
			};

			asr-cpufreq-cooling {
				compatible = "asr,cpufreq-cooling";
				status = "ok";
			};

			asr-gpufreq-cooling {
				compatible = "asr,gpufreq-cooling";
				gpu_device = "img,rgx";
				status = "ok";
			};

			asr-pa-cooling {
				compatible = "asr,cp-pa-cooling";
				status = "ok";
			};

			coresight@d5000000 {
				#address-cells = <0x1>;
				#size-cells = <0x1>;
				clock-names = "DBGCLK";
				clocks = <0xb 0x118>;
				compatible = "asr,coresight";
				ranges;
				reg = <0xd5000000 0x1000000>;
				status = "ok";
				topology = <0x4>;

				cs_cti@d5420000 {
					compatible = "asr,coresight-cti";
					reg = <0xd5420000 0x10000 0xd5520000 0x10000 0xd5620000 0x10000 0xd5720000 0x10000>;
				};

				cs_dbg@d5410000 {
					compatible = "asr,coresight-dbg";
					reg = <0xd5410000 0x10000 0xd5510000 0x10000 0xd5610000 0x10000 0xd5710000 0x10000>;
				};

				cs_pmu@d5430000 {
					compatible = "asr,coresight-pmu";
					reg = <0xd5430000 0x10000 0xd5530000 0x10000 0xd5630000 0x10000 0xd5730000 0x10000>;
				};
			};

			edgewakeup@d4019800 {
				compatible = "asr,edge-wakeup";
				interrupts = <0x0 0x27 0x4>;
				reg = <0xd4019800 0x10 0xd401e000 0x400>;
				status = "ok";
			};

			gpio@d4019000 {
				#address-cells = <0x1>;
				#gpio-cells = <0x2>;
				#size-cells = <0x1>;
				clocks = <0xb 0xd1>;
				compatible = "asr,asr-gpio";
				gpio-controller;
				interrupt-names = "gpio_mux";
				interrupts = <0x0 0x25 0x4>;
				phandle = <0x12>;
				ranges;
				reg = <0xd4019000 0x800>;

				gpio0 {
					gpio-ranges = <0x28 0x0 0x37 0x20>;
					reg-offset = <0x0>;
				};

				gpio1 {
					gpio-ranges = <0x28 0x0 0x57 0x17>;
					reg-offset = <0x4>;
				};

				gpio2 {
					gpio-ranges = <0x28 0x3 0x6e 0x1d>;
					reg-offset = <0x8>;
				};

				gpio3 {
					gpio-ranges = <0x28 0x0 0x8b 0x3 0x28 0x1c 0x34 0x1>;
					reg-offset = <0x100>;
				};
			};

			i2c@d4010800 {
				#address-cells = <0x1>;
				#size-cells = <0x0>;
				asr,adapter-id = <0x1>;
				asr,apb_clock = <0x3197500>;
				asr,dma-disable;
				asr,i2c-fast-mode;
				asr,i2c-lcr = <0x82c469f>;
				asr,i2c-wcr = <0x142a>;
				clocks = <0xb 0xc9>;
				compatible = "asr,asr-i2c";
				dma-names = "rx", "tx";
				dmas = <0x25 0x10 0x1 0x25 0xf 0x1>;
				interrupts = <0x0 0x15 0x4>;
				lpm-qos = <0x7>;
				reg = <0xd4010800 0x38>;
				status = "ok";
			};

			i2c@d4011000 {
				#address-cells = <0x1>;
				#size-cells = <0x0>;
				asr,adapter-id = <0x0>;
				asr,apb_clock = <0x3197500>;
				asr,dma-disable;
				asr,i2c-fast-mode;
				asr,i2c-lcr = <0x82c469f>;
				asr,i2c-wcr = <0x142a>;
				clocks = <0xb 0xc8>;
				compatible = "asr,asr-i2c";
				dma-names = "rx", "tx";
				dmas = <0x25 0x8 0x1 0x25 0x7 0x1>;
				interrupts = <0x0 0x14 0x4>;
				lpm-qos = <0x7>;
				reg = <0xd4011000 0x38>;
				status = "ok";
			};

			i2c@d4013800 {
				#address-cells = <0x1>;
				#size-cells = <0x0>;
				asr,adapter-id = <0x2>;
				asr,apb_clock = <0x3197500>;
				asr,dma-disable;
				asr,i2c-fast-mode;
				asr,i2c-lcr = <0x82c469f>;
				asr,i2c-wcr = <0x142a>;
				clocks = <0xb 0xca>;
				compatible = "asr,asr-i2c";
				dma-names = "rx", "tx";
				dmas = <0x25 0xe 0x1 0x25 0xd 0x1>;
				interrupts = <0x0 0x16 0x4>;
				lpm-qos = <0x7>;
				reg = <0xd4013800 0x38>;
				status = "ok";

				aw36515@63 {
					compatible = "awinic,leds_aw36515";
					reg = <0x63>;
					status = "okay";
				};
			};

			i2c@d4018800 {
				#address-cells = <0x1>;
				#size-cells = <0x0>;
				asr,adapter-id = <0x3>;
				asr,apb_clock = <0x3197500>;
				asr,clk-always-on;
				asr,dma-disable;
				asr,i2c-apdcp;
				asr,i2c-clk-rate = <0x1e84800>;
				asr,i2c-fast-mode;
				asr,i2c-lcr = <0x82c469f>;
				asr,i2c-master-code = [0e];
				asr,i2c-wcr = <0x142a>;
				clocks = <0xb 0xcb>;
				compatible = "asr,asr-i2c";
				dma-names = "rx", "tx";
				dmas = <0x25 0x12 0x1 0x25 0x11 0x1>;
				interrupts = <0x0 0x17 0x4>;
				lpm-qos = <0x7>;
				reg = <0xd4018800 0x38 0xd40b0300 0x4>;
				status = "ok";

				pm833@10 {
					#thermal-sensor-cells = <0x1>;
					bat-id = <0x0>;
					compatible = "asr,pm833";
					irq-gpio = <0x12 0x4d 0x0>;
					log-level = <0x1>;
					pinctrl-0 = <0x2a>;
					pinctrl-names = "default";
					reg = <0x10>;
					status = "ok";

					battery0 {
						age-table = <0x0 0x1 0x2 0x3 0x4 0x5 0x6 0x7 0x8 0x9 0xb 0xb 0xc 0xc 0xd 0xd 0xe 0xe 0xf 0xf 0x10 0x10 0x11 0x11 0x12 0x12 0x13 0x13 0x14 0x14 0x15 0x15 0x16 0x16 0x17 0x17 0x18 0x18 0x19 0x19 0x1a 0x1a 0x1b 0x1b 0x1c 0x1c 0x1d 0x1d 0x1e 0x1e>;
						age-table-step = <0xa>;
						bat-capacity = <0xfa0>;
						bat-capacity-mwh = <0x39d0>;
						bat-charge-current-limit = <0x0 0xbb8 0xbb8 0x3e8 0x0>;
						bat-cycle = <0x12c>;
						bat-force-power-off-th = <0xc80>;
						bat-model = "1154065P-4000mAh";
						bat-monitor-intval = <0x1e>;
						bat-temp-range = <0x0 0xa 0x28 0x37>;
						bat-vendor = "XINYUANFENG";
						bat-volt-low-th = <0xce4>;
						bat-voltage = <0x1068>;
						ntc-table = <0x458 0x36c 0x2b7 0x22c 0x1bf 0x16a 0x127 0xf2 0xc8 0xa6 0x8a 0x74 0x61 0x52 0x46 0x3c 0x33 0x2c>;
						ntc-table-start = <0x102>;
						ntc-table-step = <0x5>;
						ocv-table = <0xd3e 0xd48 0xd51 0xd5b 0xd66 0xd6f 0xd79 0xd82 0xd8a 0xd93 0xd9b 0xda2 0xda8 0xdae 0xdb5 0xdbb 0xdc1 0xdc7 0xdcb 0xdd0 0xdd4 0xdd8 0xddc 0xddf 0xde2 0xde6 0xde8 0xdeb 0xdee 0xdf1 0xdf4 0xdf6 0xdf9 0xdfc 0xdff 0xe01 0xe04 0xe07 0xe0a 0xe0d 0xe10 0xe13 0xe16 0xe19 0xe1d 0xe20 0xe23 0xe28 0xe2c 0xe31 0xe37 0xe3d 0xe43 0xe49 0xe50 0xe56 0xe5d 0xe63 0xe69 0xe70 0xe77 0xe7e 0xe86 0xe8d 0xe95 0xe9d 0xea5 0xead 0xeb5 0xebe 0xec7 0xed0 0xeda 0xee3 0xeed 0xef7 0xf01 0xf0b 0xf14 0xf1f 0xf29 0xf33 0xf3d 0xf48 0xf52 0xf5c 0xf68 0xf72 0xf7c 0xf87 0xf92 0xf9d 0xfa9 0xfb5 0xfc1 0xfcd 0xfdb 0xfeb 0xffc 0x1014>;
						ocv-table-step = <0x1>;
						soc-alart-th = <0x5>;
						soc-critical-th = <0x1>;
						soc-cycle-th = <0x50>;
						soc-high-th = <0x55>;
						soc-low-th = <0x14>;
						soc-recharge-th = <0x62>;
					};

					charger {
						cc-limit = <0xc80>;
						charger-temp-demand = <0x46>;
						charger-temp-limit = <0x64>;
						cv-limit = <0x1162>;
						fastchg-eoc = <0x96>;
						fastchg-tout = <0xc0>;
						ivbus-limit = <0xc80>;
						prechg-current = <0xc8>;
						prechg-voltage = <0x898>;
						recharge-soc-thr = <0x62>;
						recharge-voltage-thr = <0xc8>;
					};

					fuelgauge {
						ir-comp-res = <0x64>;
					};
				};

				pm853@30 {
					asr,pm853-irq-write-clear;
					asr,pmic-bd-cfg = <0x1 0x36 0x1 0x1 0x1 0x18 0xf 0xa 0x1 0x53 0x20 0x20 0x1 0xb9 0xf 0xf 0x1 0xba 0xf 0xf 0x1 0xc8 0xf 0xf 0x1 0xc9 0xf 0xf 0x1 0x12 0x21 0x21 0x1 0x65 0x10 0x10 0x1 0x3f 0x3 0x2 0x1 0x40 0x3f 0x1b 0x1 0x32 0x7f 0xc>;
					compatible = "asr,pm853";
					interrupt-parent = <0x1>;
					interrupts = <0x0 0x2b 0x4>;
					reg = <0x30>;
					status = "ok";

					battery {
					};

					debugfs {
						compatible = "asr,pm853-debugfs";
					};

					dvc {
						compatible = "asr,pm853-dvc";
					};

					gpadc {
						compatible = "asr,pm853-gpadc";
					};

					led {
						boot-on;
						compatible = "asr,pm853-led";
					};

					onkey {
						compatible = "asr,pm853-onkey";
						disable-long-key-rst = <0x0>;
						long-onkey-press-time = <0x8>;
						long-onkey-type = <0x1>;
						onkey-press-debounce-time = <0x1e>;
					};

					pmic-thermal {
						#thermal-sensor-cells = <0x1>;
						compatible = "asr,pm853-thermal";
						phandle = <0x41>;
						status = "ok";
					};

					regulator-buck1 {
						compatible = "asr,pm853-buck1";
						regulator-always-on;
						regulator-boot-on;
						regulator-max-microvolt = <0x3037c0>;
						regulator-min-microvolt = <0x75300>;
					};

					regulator-buck2 {
						compatible = "asr,pm853-buck2";
						regulator-always-on;
						regulator-boot-on;
						regulator-max-microvolt = <0x3037c0>;
						regulator-min-microvolt = <0x75300>;
					};

					regulator-buck3 {
						compatible = "asr,pm853-buck3";
						regulator-max-microvolt = <0x3037c0>;
						regulator-min-microvolt = <0x75300>;
						status = "disabled";
					};

					regulator-buck4 {
						compatible = "asr,pm853-buck4";
						regulator-always-on;
						regulator-boot-on;
						regulator-max-microvolt = <0x3037c0>;
						regulator-min-microvolt = <0x75300>;
					};

					regulator-buck5 {
						compatible = "asr,pm853-buck5";
						regulator-always-on;
						regulator-boot-on;
						regulator-max-microvolt = <0x3037c0>;
						regulator-min-microvolt = <0x75300>;
					};

					regulator-ldo1 {
						compatible = "asr,pm853-ldo1";
						regulator-max-microvolt = <0x325aa0>;
						regulator-min-microvolt = <0x124f80>;
						status = "disabled";
					};

					regulator-ldo10 {
						compatible = "asr,pm853-ldo10";
						phandle = <0x43>;
						regulator-max-microvolt = <0x325aa0>;
						regulator-min-microvolt = <0x124f80>;
					};

					regulator-ldo11 {
						compatible = "asr,pm853-ldo11";
						phandle = <0x44>;
						regulator-max-microvolt = <0x325aa0>;
						regulator-min-microvolt = <0x124f80>;
					};

					regulator-ldo12 {
						compatible = "asr,pm853-ldo12";
						phandle = <0x42>;
						regulator-max-microvolt = <0x325aa0>;
						regulator-min-microvolt = <0x124f80>;
					};

					regulator-ldo13 {
						compatible = "asr,pm853-ldo13";
						phandle = <0x31>;
						regulator-max-microvolt = <0x325aa0>;
						regulator-min-microvolt = <0x124f80>;
					};

					regulator-ldo14 {
						compatible = "asr,pm853-ldo14";
						regulator-always-on;
						regulator-boot-on;
						regulator-max-microvolt = <0x325aa0>;
						regulator-min-microvolt = <0x124f80>;
					};

					regulator-ldo15 {
						compatible = "asr,pm853-ldo15";
						phandle = <0x49>;
						regulator-max-microvolt = <0x1dc130>;
						regulator-min-microvolt = <0x124f80>;
					};

					regulator-ldo16 {
						compatible = "asr,pm853-ldo16";
						phandle = <0x4b>;
						regulator-max-microvolt = <0x325aa0>;
						regulator-min-microvolt = <0x124f80>;
					};

					regulator-ldo17 {
						compatible = "asr,pm853-ldo17";
						phandle = <0x30>;
						regulator-max-microvolt = <0x149970>;
						regulator-min-microvolt = <0xf4240>;
					};

					regulator-ldo18 {
						compatible = "asr,pm853-ldo18";
						regulator-always-on;
						regulator-boot-on;
						regulator-max-microvolt = <0x1dc130>;
						regulator-min-microvolt = <0x124f80>;
					};

					regulator-ldo19 {
						compatible = "asr,pm853-ldo19";
						regulator-always-on;
						regulator-boot-on;
						regulator-max-microvolt = <0x149970>;
						regulator-min-microvolt = <0xf4240>;
					};

					regulator-ldo2 {
						compatible = "asr,pm853-ldo2";
						regulator-always-on;
						regulator-boot-on;
						regulator-max-microvolt = <0x325aa0>;
						regulator-min-microvolt = <0x124f80>;
					};

					regulator-ldo20 {
						compatible = "asr,pm853-ldo20";
						phandle = <0x45>;
						regulator-max-microvolt = <0x149970>;
						regulator-min-microvolt = <0xf4240>;
					};

					regulator-ldo21 {
						compatible = "asr,pm853-ldo21";
						phandle = <0x4e>;
						regulator-max-microvolt = <0x1dc130>;
						regulator-min-microvolt = <0x124f80>;
					};

					regulator-ldo22 {
						compatible = "asr,pm853-ldo22";
						regulator-max-microvolt = <0x149970>;
						regulator-min-microvolt = <0xf4240>;
					};

					regulator-ldo3 {
						compatible = "asr,pm853-ldo3";
						regulator-max-microvolt = <0x325aa0>;
						regulator-min-microvolt = <0x124f80>;
						status = "disabled";
					};

					regulator-ldo4 {
						compatible = "asr,pm853-ldo4";
						phandle = <0x17>;
						regulator-max-microvolt = <0x325aa0>;
						regulator-min-microvolt = <0x124f80>;
					};

					regulator-ldo5 {
						compatible = "asr,pm853-ldo5";
						regulator-max-microvolt = <0x1cfde0>;
						regulator-min-microvolt = <0x186a00>;
						status = "disabled";
					};

					regulator-ldo5-sw {
						compatible = "asr,pm853-ldo5-sw";
						phandle = <0x48>;
						regulator-max-microvolt = <0x1b7740>;
						regulator-min-microvolt = <0x1b7740>;
					};

					regulator-ldo6 {
						compatible = "asr,pm853-ldo6";
						phandle = <0x29>;
						regulator-max-microvolt = <0x325aa0>;
						regulator-min-microvolt = <0x124f80>;
					};

					regulator-ldo7 {
						compatible = "asr,pm853-ldo7";
						regulator-max-microvolt = <0x325aa0>;
						regulator-min-microvolt = <0x124f80>;
						status = "disabled";
					};

					regulator-ldo8 {
						compatible = "asr,pm853-ldo8";
						regulator-max-microvolt = <0x325aa0>;
						regulator-min-microvolt = <0x124f80>;
						status = "disabled";
					};

					regulator-ldo9 {
						compatible = "asr,pm853-ldo9";
						phandle = <0x18>;
						regulator-max-microvolt = <0x325aa0>;
						regulator-min-microvolt = <0x124f80>;
					};

					rtc {
						compatible = "asr,pm853-rtc";
						status = "disabled";
					};

					vibra {
						compatible = "asr,pm853-vibra";
						vib-ldo;
						vib-supply = <0x29>;
					};

					wdt {
						compatible = "asr,pm853-wdt";
						pm853,wdt-disabled;
						pm853,wdt_reset_soc;
					};
				};
			};

			i2c@d4020000 {
				#address-cells = <0x1>;
				#size-cells = <0x0>;
				asr,adapter-id = <0x4>;
				asr,apb_clock = <0x3197500>;
				asr,dma-disable;
				asr,i2c-clk-rate = <0x1e84800>;
				asr,i2c-lcr = <0x82c469f>;
				asr,i2c-master-code = [0e];
				asr,i2c-wcr = <0x142a>;
				clocks = <0xb 0xcc>;
				compatible = "asr,asr-i2c";
				dma-names = "rx", "tx";
				dmas = <0x25 0x16 0x1 0x25 0x15 0x1>;
				interrupts = <0x0 0x18 0x4>;
				lpm-qos = <0x7>;
				reg = <0xd4020000 0x38>;
				status = "disabled";
			};

			i2c@d4020800 {
				#address-cells = <0x1>;
				#size-cells = <0x0>;
				asr,adapter-id = <0x5>;
				asr,apb_clock = <0x3197500>;
				asr,dma-disable;
				asr,i2c-clk-rate = <0x1e84800>;
				asr,i2c-fast-mode;
				asr,i2c-lcr = <0x82c469f>;
				asr,i2c-master-code = [0e];
				asr,i2c-wcr = <0x142a>;
				clocks = <0xb 0xcd>;
				compatible = "asr,asr-i2c";
				dma-names = "rx", "tx";
				dmas = <0x25 0x18 0x1 0x25 0x17 0x1>;
				interrupts = <0x0 0x19 0x4>;
				lpm-qos = <0x7>;
				reg = <0xd4020800 0x38>;
				status = "ok";

				gcore_tp@26 {
					compatible = "gcore,touchscreen";
					gcore,irq-gpio = <0x12 0x7 0x0>;
					gcore,rst-gpio = <0x12 0x8 0x0>;
					phandle = <0x32>;
					pinctrl-0 = <0x2b>;
					pinctrl-names = "default";
					reg = <0x26>;
					status = "disabled";
				};
			};

			i2c@d4021000 {
				#address-cells = <0x1>;
				#size-cells = <0x0>;
				asr,adapter-id = <0x6>;
				asr,apb_clock = <0x3197500>;
				asr,dma-disable;
				asr,i2c-clk-rate = <0x1e84800>;
				asr,i2c-fast-mode;
				asr,i2c-lcr = <0x82c469f>;
				asr,i2c-master-code = [0e];
				asr,i2c-wcr = <0x142a>;
				clocks = <0xb 0xce>;
				compatible = "asr,asr-i2c";
				dma-names = "rx", "tx";
				dmas = <0x25 0x1a 0x1 0x25 0x19 0x1>;
				interrupts = <0x0 0x1a 0x4>;
				lpm-qos = <0x7>;
				reg = <0xd4021000 0x38>;
				status = "ok";

				cst78xx@15 {
					compatible = "hynitron,cst78xx";
					irq-gpio = <0x12 0x18 0x0>;
					reg = <0x15>;
					resolution = <0x168 0x168>;
					rst-gpio = <0x12 0x19 0x0>;
					status = "disabled";
				};

				ft6x36@38 {
					compatible = "fts,ft6x36";
					irq-gpio = <0x12 0x18 0x0>;
					real-resolution = <0xf0 0xc8>;
					reg = <0x38>;
					resolution = <0xf0 0xf0>;
					rst-gpio = <0x12 0x19 0x0>;
					status = "okay";
				};
			};

			i2c@d4021800 {
				#address-cells = <0x1>;
				#size-cells = <0x0>;
				asr,adapter-id = <0x7>;
				asr,apb_clock = <0x3197500>;
				asr,dma-disable;
				asr,i2c-clk-rate = <0x1e84800>;
				asr,i2c-fast-mode;
				asr,i2c-lcr = <0x82c469f>;
				asr,i2c-master-code = [0e];
				asr,i2c-wcr = <0x142a>;
				clocks = <0xb 0xcf>;
				compatible = "asr,asr-i2c";
				dma-names = "rx", "tx";
				dmas = <0x25 0x1c 0x1 0x25 0x1b 0x1>;
				interrupts = <0x0 0x1b 0x4>;
				lpm-qos = <0x7>;
				reg = <0xd4021800 0x38>;
				status = "disabled";
			};

			i2c@d4022000 {
				#address-cells = <0x1>;
				#size-cells = <0x0>;
				asr,adapter-id = <0x8>;
				asr,apb_clock = <0x3197500>;
				asr,dma-disable;
				asr,i2c-clk-rate = <0x1e84800>;
				asr,i2c-fast-mode;
				asr,i2c-lcr = <0x82c469f>;
				asr,i2c-master-code = [0e];
				asr,i2c-wcr = <0x142a>;
				clocks = <0xb 0xd0>;
				compatible = "asr,asr-i2c";
				dma-names = "rx", "tx";
				dmas = <0x25 0x1e 0x1 0x25 0x1d 0x1>;
				interrupts = <0x0 0x1c 0x4>;
				lpm-qos = <0x7>;
				reg = <0xd4022000 0x64>;
				status = "disabled";
			};

			pdma@d4000000 {
				#dma-cells = <0x2>;
				#dma-channels = <0x10>;
				compatible = "asr,pdma-1.0";
				interrupts = <0x0 0x38 0x4>;
				lpm-qos = <0x7>;
				max-burst-size = <0x40>;
				phandle = <0x25>;
				reg = <0xd4000000 0x10000>;
				reserved-channels = <0x11>;
				status = "ok";
			};

			pinmux@d401e000 {
				#address-cells = <0x1>;
				#gpio-range-cells = <0x3>;
				#pinctrl-cells = <0x1>;
				#size-cells = <0x1>;
				compatible = "pinconf-single";
				phandle = <0x28>;
				pinctrl-0 = <0x26 0x27>;
				pinctrl-names = "default";
				pinctrl-single,function-mask = <0x7>;
				pinctrl-single,register-width = <0x20>;
				ranges;
				reg = <0xd401e000 0x400>;
				status = "ok";

				a4_spi_lcd_3line2lane {
					pinctrl-single,bias-pulldown = <0x8000 0xa000 0x8000 0xa000>;
					pinctrl-single,bias-pullup = <0xc000 0xc000 0x0 0xc000>;
					pinctrl-single,drive-strength = <0x1000 0x1800>;
					pinctrl-single,input-schmitt = <0x0 0x30>;
					pinctrl-single,input-schmitt-enable = <0x40 0x0 0x40 0x40>;
					pinctrl-single,low-power-mode = <0x0 0x388>;
					pinctrl-single,pins = <0xc 0x2 0x1c 0x2 0x2c 0x2 0x5c 0x2 0x60 0x2>;
				};

				a4_spi_lcd_4line1lane {
					pinctrl-single,bias-pulldown = <0x8000 0xa000 0x8000 0xa000>;
					pinctrl-single,bias-pullup = <0xc000 0xc000 0x0 0xc000>;
					pinctrl-single,drive-strength = <0x1000 0x1800>;
					pinctrl-single,input-schmitt = <0x0 0x30>;
					pinctrl-single,input-schmitt-enable = <0x40 0x0 0x40 0x40>;
					pinctrl-single,low-power-mode = <0x0 0x388>;
					pinctrl-single,pins = <0xc 0x2 0x1c 0x2 0x2c 0x2 0x5c 0x2 0x60 0x3>;
				};

				a4_spi_lcd_qspi {
					pinctrl-single,bias-pulldown = <0x8000 0xa000 0x8000 0xa000>;
					pinctrl-single,bias-pullup = <0xc000 0xc000 0x0 0xc000>;
					pinctrl-single,drive-strength = <0x1000 0x1800>;
					pinctrl-single,input-schmitt = <0x0 0x30>;
					pinctrl-single,input-schmitt-enable = <0x40 0x0 0x40 0x40>;
					pinctrl-single,low-power-mode = <0x0 0x388>;
					pinctrl-single,pins = <0xc 0x2 0x1c 0x2 0x2c 0x2 0x5c 0x2 0x60 0x2 0x38 0x3 0x44 0x3>;
				};

				btl_ts_pmx_func0 {
					pinctrl-single,bias-pulldown = <0x8000 0xa000 0x8000 0xa000>;
					pinctrl-single,bias-pullup = <0xc000 0xc000 0x0 0xc000>;
					pinctrl-single,drive-strength = <0x1000 0x1800>;
					pinctrl-single,input-schmitt = <0x0 0x30>;
					pinctrl-single,input-schmitt-enable = <0x40 0x0 0x40 0x40>;
					pinctrl-single,low-power-mode = <0x0 0x388>;
					pinctrl-single,pins = <0x20 0x0>;
				};

				ccic1_pmx_func1 {
					pinctrl-single,bias-pulldown = <0x0 0xa000 0x0 0xa000>;
					pinctrl-single,bias-pullup = <0x0 0xc000 0x0 0xc000>;
					pinctrl-single,drive-strength = <0x1000 0x1800>;
					pinctrl-single,input-schmitt = <0x0 0x30>;
					pinctrl-single,input-schmitt-enable = <0x40 0x0 0x40 0x40>;
					pinctrl-single,low-power-mode = <0x0 0x388>;
					pinctrl-single,pins = <0x28 0x0 0x34 0x0 0x40 0x1>;
				};

				ccic2_pmx_func1 {
					pinctrl-single,bias-pulldown = <0x0 0xa000 0x0 0xa000>;
					pinctrl-single,bias-pullup = <0x0 0xc000 0x0 0xc000>;
					pinctrl-single,drive-strength = <0x1000 0x1800>;
					pinctrl-single,input-schmitt = <0x0 0x30>;
					pinctrl-single,input-schmitt-enable = <0x40 0x0 0x40 0x40>;
					pinctrl-single,low-power-mode = <0x0 0x388>;
					pinctrl-single,pins = <0x2c 0x0 0x38 0x0 0x44 0x1>;
				};

				ccic3_pmx_func1 {
					pinctrl-single,bias-pulldown = <0x0 0xa000 0x0 0xa000>;
					pinctrl-single,bias-pullup = <0x0 0xc000 0x0 0xc000>;
					pinctrl-single,drive-strength = <0x1000 0x1800>;
					pinctrl-single,input-schmitt = <0x0 0x30>;
					pinctrl-single,input-schmitt-enable = <0x40 0x0 0x40 0x40>;
					pinctrl-single,low-power-mode = <0x0 0x388>;
					pinctrl-single,pins = <0x30 0x0 0x3c 0x0 0x48 0x1>;
				};

				evb_a0_mfp_pins_group_0 {
					phandle = <0x26>;
					pinctrl-single,bias-pulldown = <0x0 0xa000 0x0 0xa000>;
					pinctrl-single,bias-pullup = <0x0 0xc000 0x0 0xc000>;
					pinctrl-single,drive-strength = <0x1000 0x1800>;
					pinctrl-single,input-schmitt = <0x0 0x30>;
					pinctrl-single,input-schmitt-enable = <0x40 0x0 0x40 0x40>;
					pinctrl-single,low-power-mode = <0x0 0x388>;
					pinctrl-single,pins = <0x10 0x1 0x14 0x1 0x28 0x0 0x30 0x0 0x34 0x0 0x3c 0x0 0x40 0x1 0x48 0x1 0x4c 0x1 0x50 0x1 0x54 0x1 0x58 0x1 0x64 0x0 0x214 0x1 0x218 0x1 0x21c 0x0 0x220 0x2 0x224 0x0 0x228 0x2 0x22c 0x2 0x230 0x1 0x234 0x1 0x23c 0x1 0x240 0x0 0x244 0x0 0x248 0x0 0x24c 0x0 0x250 0x0 0x268 0x0 0x26c 0x0 0x270 0x0 0x274 0x0 0x278 0x2 0x27c 0x2 0x280 0x2 0x284 0x2 0x288 0x0 0x28c 0x0 0x290 0x0 0x294 0x0 0x298 0x0 0x29c 0x0 0x2a0 0x0 0x2a8 0x0 0x2ac 0x0 0x2b4 0x0 0x2c8 0x0 0x2d0 0x0 0x2e0 0x0 0x2ec 0x0 0x2f0 0x0 0x2f4 0x0 0x2f8 0x0 0x2fc 0x0 0x300 0x0 0x314 0x1 0x318 0x1 0x320 0x1 0x33c 0x1 0x340 0x1 0x344 0x1 0x348 0x1 0x350 0x1 0x354 0x0 0x358 0x0 0x35c 0x0 0x360 0x0 0x364 0x1 0x368 0x1 0x36c 0x0 0x370 0x0 0x374 0x1 0x378 0x1 0x38c 0x0 0x398 0x1 0x3a0 0x1 0x204 0x0>;
				};

				evb_a0_mfp_pins_group_1 {
					phandle = <0x27>;
					pinctrl-single,bias-pulldown = <0x8000 0x8000 0x0 0xa000>;
					pinctrl-single,bias-pullup = <0x8000 0x8000 0x0 0xc000>;
					pinctrl-single,drive-strength = <0x1000 0x1800>;
					pinctrl-single,input-schmitt = <0x0 0x30>;
					pinctrl-single,input-schmitt-enable = <0x40 0x0 0x40 0x40>;
					pinctrl-single,low-power-mode = <0x0 0x388>;
					pinctrl-single,pins = <0x8 0x0 0x18 0x2 0x254 0x0 0x2c0 0x1 0x2c4 0x1 0x2d4 0x0 0x31c 0x1 0x34c 0x0>;
				};

				evb_mfp_pins_group_0 {
					pinctrl-single,bias-pulldown = <0xa000 0xa000 0x0 0xa000>;
					pinctrl-single,bias-pullup = <0x8000 0xc000 0x8000 0xc000>;
					pinctrl-single,drive-strength = <0x1000 0x1800>;
					pinctrl-single,input-schmitt = <0x0 0x30>;
					pinctrl-single,input-schmitt-enable = <0x40 0x0 0x40 0x40>;
					pinctrl-single,low-power-mode = <0x0 0x388>;
					pinctrl-single,pins = <0x394 0x0>;
				};

				evb_mfp_pins_group_1 {
					pinctrl-single,bias-pulldown = <0x0 0xa000 0x0 0xa000>;
					pinctrl-single,bias-pullup = <0x0 0xc000 0x0 0xc000>;
					pinctrl-single,drive-strength = <0x1000 0x1800>;
					pinctrl-single,input-schmitt = <0x0 0x30>;
					pinctrl-single,input-schmitt-enable = <0x40 0x0 0x40 0x40>;
					pinctrl-single,low-power-mode = <0x0 0x388>;
					pinctrl-single,pins = <0x20 0x0 0x10 0x1 0x14 0x1 0x258 0x1 0x25c 0x1 0x5c 0x1 0x60 0x1 0x364 0x1 0x368 0x1 0x2a0 0x1 0x2a4 0x1 0x220 0x1 0x224 0x1 0x228 0x1 0x22c 0x1 0x33c 0x1 0x340 0x1 0x344 0x1 0x348 0x1 0x2ec 0x1 0x2f0 0x1 0x2f4 0x1 0x2f8 0x1 0x2fc 0x1 0x300 0x1 0x304 0x1 0x308 0x1 0x298 0x1 0x29c 0x1 0x248 0x1 0x24c 0x1 0x250 0x1 0x254 0x1 0x64 0x0 0x68 0x0 0x24 0x0 0x314 0x1 0x318 0x1 0x31c 0x1 0x320 0x1 0x28 0x0 0x2c 0x0 0x30 0x0 0x34 0x0 0x38 0x0 0x3c 0x0 0x40 0x1 0x44 0x1 0x48 0x1>;
				};

				goodix_ts_pmx_func0 {
					phandle = <0x2b>;
					pinctrl-single,bias-pulldown = <0xa000 0xa000 0x0 0xa000>;
					pinctrl-single,bias-pullup = <0x8000 0xc000 0x8000 0xc000>;
					pinctrl-single,drive-strength = <0x1000 0x1800>;
					pinctrl-single,input-schmitt = <0x0 0x30>;
					pinctrl-single,input-schmitt-enable = <0x40 0x0 0x40 0x40>;
					pinctrl-single,low-power-mode = <0x0 0x388>;
					pinctrl-single,pins = <0x20 0x0 0x24 0x0>;
				};

				gpio-range {
					#pinctrl-single,gpio-range-cells = <0x3>;
				};

				gpio126_pmx_func0 {
					phandle = <0x1a>;
					pinctrl-single,bias-pulldown = <0x8000 0xa000 0x8000 0xa000>;
					pinctrl-single,bias-pullup = <0xc000 0xc000 0x0 0xc000>;
					pinctrl-single,drive-strength = <0x1000 0x1800>;
					pinctrl-single,input-schmitt = <0x0 0x30>;
					pinctrl-single,input-schmitt-enable = <0x40 0x0 0x40 0x40>;
					pinctrl-single,low-power-mode = <0x288 0x388>;
					pinctrl-single,pins = <0x39c 0x0>;
				};

				gpio126_pmx_func2 {
					phandle = <0x1f>;
					pinctrl-single,bias-pulldown = <0x0 0xa000 0x0 0xa000>;
					pinctrl-single,bias-pullup = <0x0 0xc000 0x0 0xc000>;
					pinctrl-single,drive-strength = <0x1000 0x1800>;
					pinctrl-single,input-schmitt = <0x0 0x30>;
					pinctrl-single,input-schmitt-enable = <0x40 0x0 0x40 0x40>;
					pinctrl-single,low-power-mode = <0x0 0x388>;
					pinctrl-single,pins = <0x39c 0x2>;
				};

				gpio51_pmx_func0 {
					pinctrl-single,bias-pulldown = <0x8000 0xa000 0x8000 0xa000>;
					pinctrl-single,bias-pullup = <0xc000 0xc000 0x0 0xc000>;
					pinctrl-single,drive-strength = <0x1000 0x1800>;
					pinctrl-single,input-schmitt = <0x0 0x30>;
					pinctrl-single,input-schmitt-enable = <0x40 0x0 0x40 0x40>;
					pinctrl-single,low-power-mode = <0x288 0x388>;
					pinctrl-single,pins = <0x270 0x0>;
				};

				gpio51_pmx_func2 {
					pinctrl-single,bias-pulldown = <0x0 0xa000 0x0 0xa000>;
					pinctrl-single,bias-pullup = <0x0 0xc000 0x0 0xc000>;
					pinctrl-single,drive-strength = <0x1000 0x1800>;
					pinctrl-single,input-schmitt = <0x0 0x30>;
					pinctrl-single,input-schmitt-enable = <0x40 0x0 0x40 0x40>;
					pinctrl-single,low-power-mode = <0x0 0x388>;
					pinctrl-single,pins = <0x270 0x2>;
				};

				mipi_te_func {
					pinctrl-single,bias-pulldown = <0x0 0xa000 0x0 0xa000>;
					pinctrl-single,bias-pullup = <0x0 0xc000 0x0 0xc000>;
					pinctrl-single,drive-strength = <0x1000 0x1800>;
					pinctrl-single,input-schmitt = <0x0 0x30>;
					pinctrl-single,input-schmitt-enable = <0x40 0x0 0x40 0x40>;
					pinctrl-single,low-power-mode = <0x0 0x388>;
					pinctrl-single,pins = <0x4 0x1>;
				};

				mipi_te_gpio {
					pinctrl-single,bias-pulldown = <0x0 0xa000 0x0 0xa000>;
					pinctrl-single,bias-pullup = <0x0 0xc000 0x0 0xc000>;
					pinctrl-single,drive-strength = <0x1000 0x1800>;
					pinctrl-single,input-schmitt = <0x0 0x30>;
					pinctrl-single,input-schmitt-enable = <0x40 0x0 0x40 0x40>;
					pinctrl-single,low-power-mode = <0x0 0x388>;
					pinctrl-single,pins = <0x4 0x0>;
				};

				pm833_pin_func0 {
					phandle = <0x2a>;
					pinctrl-single,bias-pulldown = <0x8000 0xa000 0x8000 0xa000>;
					pinctrl-single,bias-pullup = <0xc000 0xc000 0x0 0xc000>;
					pinctrl-single,drive-strength = <0x1000 0x1800>;
					pinctrl-single,input-schmitt = <0x0 0x30>;
					pinctrl-single,input-schmitt-enable = <0x40 0x0 0x40 0x40>;
					pinctrl-single,low-power-mode = <0x0 0x388>;
					pinctrl-single,pins = <0x2d8 0x0>;
				};

				sdcard_clk_pmx_func0 {
					phandle = <0x1b>;
					pinctrl-single,bias-pulldown = <0xa000 0xa000 0x0 0xa000>;
					pinctrl-single,bias-pullup = <0x8000 0xc000 0x8000 0xc000>;
					pinctrl-single,drive-strength = <0x800 0x1800>;
					pinctrl-single,input-schmitt = <0x0 0x30>;
					pinctrl-single,input-schmitt-enable = <0x40 0x0 0x40 0x40>;
					pinctrl-single,low-power-mode = <0x208 0x388>;
					pinctrl-single,pins = <0x1cc 0x0>;
				};

				sdcard_clk_pmx_func0_fast {
					phandle = <0x1d>;
					pinctrl-single,bias-pulldown = <0xa000 0xa000 0x0 0xa000>;
					pinctrl-single,bias-pullup = <0x8000 0xc000 0x8000 0xc000>;
					pinctrl-single,drive-strength = <0x1800 0x1800>;
					pinctrl-single,input-schmitt = <0x0 0x30>;
					pinctrl-single,input-schmitt-enable = <0x40 0x0 0x40 0x40>;
					pinctrl-single,low-power-mode = <0x208 0x388>;
					pinctrl-single,pins = <0x1cc 0x0>;
				};

				sdcard_pmx_func0 {
					phandle = <0x19>;
					pinctrl-single,bias-pulldown = <0x8000 0xa000 0x8000 0xa000>;
					pinctrl-single,bias-pullup = <0xc000 0xc000 0x0 0xc000>;
					pinctrl-single,drive-strength = <0x800 0x1800>;
					pinctrl-single,input-schmitt = <0x0 0x30>;
					pinctrl-single,input-schmitt-enable = <0x40 0x0 0x40 0x40>;
					pinctrl-single,low-power-mode = <0x0 0x388>;
					pinctrl-single,pins = <0x1b8 0x0 0x1bc 0x0 0x1c0 0x0 0x1c4 0x0 0x1c8 0x0>;
				};

				sdcard_pmx_func0_fast {
					phandle = <0x1c>;
					pinctrl-single,bias-pulldown = <0x8000 0xa000 0x8000 0xa000>;
					pinctrl-single,bias-pullup = <0xc000 0xc000 0x0 0xc000>;
					pinctrl-single,drive-strength = <0x1800 0x1800>;
					pinctrl-single,input-schmitt = <0x0 0x30>;
					pinctrl-single,input-schmitt-enable = <0x40 0x0 0x40 0x40>;
					pinctrl-single,low-power-mode = <0x0 0x388>;
					pinctrl-single,pins = <0x1b8 0x0 0x1bc 0x0 0x1c0 0x0 0x1c4 0x0 0x1c8 0x0>;
				};

				sdcard_pmx_func2 {
					phandle = <0x1e>;
					pinctrl-single,bias-pulldown = <0x0 0xa000 0x0 0xa000>;
					pinctrl-single,bias-pullup = <0x0 0xc000 0x0 0xc000>;
					pinctrl-single,drive-strength = <0x1000 0x1800>;
					pinctrl-single,input-schmitt = <0x0 0x30>;
					pinctrl-single,input-schmitt-enable = <0x40 0x0 0x40 0x40>;
					pinctrl-single,low-power-mode = <0x0 0x388>;
					pinctrl-single,pins = <0x1b8 0x2 0x1bc 0x2 0x1c0 0x2 0x1c4 0x2 0x1c8 0x2 0x1cc 0x2>;
				};

				sdio_clk_pmx_func1 {
					phandle = <0x21>;
					pinctrl-single,bias-pulldown = <0x0 0xa000 0x0 0xa000>;
					pinctrl-single,bias-pullup = <0x0 0xc000 0x0 0xc000>;
					pinctrl-single,drive-strength = <0x1000 0x1800>;
					pinctrl-single,input-schmitt = <0x0 0x30>;
					pinctrl-single,input-schmitt-enable = <0x40 0x0 0x40 0x40>;
					pinctrl-single,low-power-mode = <0x208 0x388>;
					pinctrl-single,pins = <0x338 0x1>;
				};

				sdio_clk_pmx_func1_fast {
					phandle = <0x23>;
					pinctrl-single,bias-pulldown = <0x0 0xa000 0x0 0xa000>;
					pinctrl-single,bias-pullup = <0x0 0xc000 0x0 0xc000>;
					pinctrl-single,drive-strength = <0x1800 0x1800>;
					pinctrl-single,input-schmitt = <0x0 0x30>;
					pinctrl-single,input-schmitt-enable = <0x40 0x0 0x40 0x40>;
					pinctrl-single,low-power-mode = <0x208 0x388>;
					pinctrl-single,pins = <0x338 0x1>;
				};

				sdio_pmx_func1 {
					phandle = <0x20>;
					pinctrl-single,bias-pulldown = <0x0 0xa000 0x0 0xa000>;
					pinctrl-single,bias-pullup = <0x0 0xc000 0x0 0xc000>;
					pinctrl-single,drive-strength = <0x1000 0x1800>;
					pinctrl-single,input-schmitt = <0x0 0x30>;
					pinctrl-single,input-schmitt-enable = <0x40 0x0 0x40 0x40>;
					pinctrl-single,low-power-mode = <0x0 0x388>;
					pinctrl-single,pins = <0x324 0x1 0x328 0x1 0x32c 0x1 0x330 0x1 0x334 0x1>;
				};

				sdio_pmx_func1_fast {
					phandle = <0x22>;
					pinctrl-single,bias-pulldown = <0x0 0xa000 0x0 0xa000>;
					pinctrl-single,bias-pullup = <0x0 0xc000 0x0 0xc000>;
					pinctrl-single,drive-strength = <0x1800 0x1800>;
					pinctrl-single,input-schmitt = <0x0 0x30>;
					pinctrl-single,input-schmitt-enable = <0x40 0x0 0x40 0x40>;
					pinctrl-single,low-power-mode = <0x0 0x388>;
					pinctrl-single,pins = <0x324 0x1 0x328 0x1 0x32c 0x1 0x330 0x1 0x334 0x1>;
				};

				sh_i2c_pmx_func4 {
					phandle = <0x4c>;
					pinctrl-single,bias-pulldown = <0x0 0xa000 0x0 0xa000>;
					pinctrl-single,bias-pullup = <0x0 0xc000 0x0 0xc000>;
					pinctrl-single,drive-strength = <0x1000 0x1800>;
					pinctrl-single,input-schmitt = <0x0 0x30>;
					pinctrl-single,input-schmitt-enable = <0x40 0x0 0x40 0x40>;
					pinctrl-single,low-power-mode = <0x0 0x388>;
					pinctrl-single,pins = <0x2b8 0x1 0x2bc 0x1>;
				};

				sim_card_pins_group_0 {
					phandle = <0x4d>;
					pinctrl-single,bias-pulldown = <0x8000 0xa000 0x8000 0xa000>;
					pinctrl-single,bias-pullup = <0xc000 0xc000 0x0 0xc000>;
					pinctrl-single,drive-strength = <0x1000 0x1800>;
					pinctrl-single,input-schmitt = <0x0 0x30>;
					pinctrl-single,input-schmitt-enable = <0x40 0x0 0x40 0x40>;
					pinctrl-single,low-power-mode = <0x0 0x388>;
					pinctrl-single,pins = <0x2e4 0x0 0x2e8 0x0>;
				};

				spi_lcd_3line2lane {
					phandle = <0x3c>;
					pinctrl-single,bias-pulldown = <0x8000 0xa000 0x8000 0xa000>;
					pinctrl-single,bias-pullup = <0xc000 0xc000 0x0 0xc000>;
					pinctrl-single,drive-strength = <0x1000 0x1800>;
					pinctrl-single,input-schmitt = <0x0 0x30>;
					pinctrl-single,input-schmitt-enable = <0x40 0x0 0x40 0x40>;
					pinctrl-single,low-power-mode = <0x0 0x388>;
					pinctrl-single,pins = <0xc 0x2 0x1c 0x2 0x2c 0x2 0x5c 0x2 0x60 0x2>;
				};

				spi_lcd_4line1lane {
					phandle = <0x3d>;
					pinctrl-single,bias-pulldown = <0x8000 0xa000 0x8000 0xa000>;
					pinctrl-single,bias-pullup = <0xc000 0xc000 0x0 0xc000>;
					pinctrl-single,drive-strength = <0x1000 0x1800>;
					pinctrl-single,input-schmitt = <0x0 0x30>;
					pinctrl-single,input-schmitt-enable = <0x40 0x0 0x40 0x40>;
					pinctrl-single,low-power-mode = <0x0 0x388>;
					pinctrl-single,pins = <0xc 0x2 0x1c 0x2 0x2c 0x2 0x5c 0x2 0x60 0x3>;
				};

				spi_lcd_qspi {
					phandle = <0x3b>;
					pinctrl-single,bias-pulldown = <0x8000 0xa000 0x8000 0xa000>;
					pinctrl-single,bias-pullup = <0xc000 0xc000 0x0 0xc000>;
					pinctrl-single,drive-strength = <0x1000 0x1800>;
					pinctrl-single,input-schmitt = <0x0 0x30>;
					pinctrl-single,input-schmitt-enable = <0x40 0x0 0x40 0x40>;
					pinctrl-single,low-power-mode = <0x0 0x388>;
					pinctrl-single,pins = <0xc 0x2 0x1c 0x2 0x2c 0x2 0x5c 0x2 0x60 0x2 0x38 0x3 0x44 0x3>;
				};

				ssp0_pmx_func0 {
					pinctrl-single,bias-pulldown = <0xa000 0xa000 0x0 0xa000>;
					pinctrl-single,bias-pullup = <0x8000 0xc000 0x8000 0xc000>;
					pinctrl-single,drive-strength = <0x1000 0x1800>;
					pinctrl-single,input-schmitt = <0x0 0x30>;
					pinctrl-single,input-schmitt-enable = <0x40 0x0 0x40 0x40>;
					pinctrl-single,low-power-mode = <0x0 0x388>;
					pinctrl-single,pins = <0x37c 0x1 0x384 0x1 0x388 0x1>;
				};

				ssp0_pmx_func1 {
					pinctrl-single,bias-pulldown = <0x8000 0xa000 0x8000 0xa000>;
					pinctrl-single,bias-pullup = <0xc000 0xc000 0x0 0xc000>;
					pinctrl-single,drive-strength = <0x1000 0x1800>;
					pinctrl-single,input-schmitt = <0x0 0x30>;
					pinctrl-single,input-schmitt-enable = <0x40 0x0 0x40 0x40>;
					pinctrl-single,low-power-mode = <0x0 0x388>;
					pinctrl-single,pins = <0x380 0x1>;
				};

				twsi0_pmx_func0 {
					pinctrl-single,bias-pulldown = <0x0 0xa000 0x0 0xa000>;
					pinctrl-single,bias-pullup = <0x0 0xc000 0x0 0xc000>;
					pinctrl-single,drive-strength = <0x1000 0x1800>;
					pinctrl-single,input-schmitt = <0x0 0x30>;
					pinctrl-single,input-schmitt-enable = <0x40 0x0 0x40 0x40>;
					pinctrl-single,low-power-mode = <0x0 0x388>;
					pinctrl-single,pins = <0x4c 0x0 0x50 0x0>;
				};

				twsi0_pmx_func1 {
					pinctrl-single,bias-pulldown = <0x0 0xa000 0x0 0xa000>;
					pinctrl-single,bias-pullup = <0x0 0xc000 0x0 0xc000>;
					pinctrl-single,drive-strength = <0x1000 0x1800>;
					pinctrl-single,input-schmitt = <0x0 0x30>;
					pinctrl-single,input-schmitt-enable = <0x40 0x0 0x40 0x40>;
					pinctrl-single,low-power-mode = <0x0 0x388>;
					pinctrl-single,pins = <0x4c 0x1 0x50 0x1>;
				};

				twsi0_pmx_func2 {
					pinctrl-single,bias-pulldown = <0x0 0xa000 0x0 0xa000>;
					pinctrl-single,bias-pullup = <0x0 0xc000 0x0 0xc000>;
					pinctrl-single,drive-strength = <0x1000 0x1800>;
					pinctrl-single,input-schmitt = <0x0 0x30>;
					pinctrl-single,input-schmitt-enable = <0x40 0x0 0x40 0x40>;
					pinctrl-single,low-power-mode = <0x0 0x388>;
					pinctrl-single,pins = <0x4c 0x2 0x50 0x2>;
				};

				twsi1_pmx_func0 {
					pinctrl-single,bias-pulldown = <0x0 0xa000 0x0 0xa000>;
					pinctrl-single,bias-pullup = <0x0 0xc000 0x0 0xc000>;
					pinctrl-single,drive-strength = <0x1000 0x1800>;
					pinctrl-single,input-schmitt = <0x0 0x30>;
					pinctrl-single,input-schmitt-enable = <0x40 0x0 0x40 0x40>;
					pinctrl-single,low-power-mode = <0x0 0x388>;
					pinctrl-single,pins = <0x54 0x0 0x58 0x0>;
				};

				twsi1_pmx_func1 {
					pinctrl-single,bias-pulldown = <0x0 0xa000 0x0 0xa000>;
					pinctrl-single,bias-pullup = <0x0 0xc000 0x0 0xc000>;
					pinctrl-single,drive-strength = <0x1000 0x1800>;
					pinctrl-single,input-schmitt = <0x0 0x30>;
					pinctrl-single,input-schmitt-enable = <0x40 0x0 0x40 0x40>;
					pinctrl-single,low-power-mode = <0x0 0x388>;
					pinctrl-single,pins = <0x54 0x1 0x58 0x1>;
				};

				twsi1_pmx_func2 {
					pinctrl-single,bias-pulldown = <0x0 0xa000 0x0 0xa000>;
					pinctrl-single,bias-pullup = <0x0 0xc000 0x0 0xc000>;
					pinctrl-single,drive-strength = <0x1000 0x1800>;
					pinctrl-single,input-schmitt = <0x0 0x30>;
					pinctrl-single,input-schmitt-enable = <0x40 0x0 0x40 0x40>;
					pinctrl-single,low-power-mode = <0x0 0x388>;
					pinctrl-single,pins = <0x54 0x2 0x58 0x2>;
				};

				twsi4_pmx_func1 {
					pinctrl-single,bias-pulldown = <0x0 0xa000 0x0 0xa000>;
					pinctrl-single,bias-pullup = <0x0 0xc000 0x0 0xc000>;
					pinctrl-single,drive-strength = <0x1000 0x1800>;
					pinctrl-single,input-schmitt = <0x0 0x30>;
					pinctrl-single,input-schmitt-enable = <0x40 0x0 0x40 0x40>;
					pinctrl-single,low-power-mode = <0x0 0x388>;
					pinctrl-single,pins = <0x230 0x1 0x234 0x1>;
				};

				twsi8_pmx_func1 {
					pinctrl-single,bias-pulldown = <0x0 0xa000 0x0 0xa000>;
					pinctrl-single,bias-pullup = <0x0 0xc000 0x0 0xc000>;
					pinctrl-single,drive-strength = <0x1000 0x1800>;
					pinctrl-single,input-schmitt = <0x0 0x30>;
					pinctrl-single,input-schmitt-enable = <0x40 0x0 0x40 0x40>;
					pinctrl-single,low-power-mode = <0x0 0x388>;
					pinctrl-single,pins = <0x260 0x1 0x264 0x1>;
				};

				uart2_pmx_func1 {
					pinctrl-single,bias-pulldown = <0x0 0xa000 0x0 0xa000>;
					pinctrl-single,bias-pullup = <0x0 0xc000 0x0 0xc000>;
					pinctrl-single,drive-strength = <0x1000 0x1800>;
					pinctrl-single,input-schmitt = <0x0 0x30>;
					pinctrl-single,input-schmitt-enable = <0x40 0x0 0x40 0x40>;
					pinctrl-single,low-power-mode = <0x0 0x388>;
					pinctrl-single,pins = <0x384 0x2 0x388 0x2>;
				};

				uart2_pmx_func2 {
					pinctrl-single,bias-pulldown = <0xa000 0xa000 0x0 0xa000>;
					pinctrl-single,bias-pullup = <0x8000 0xc000 0x8000 0xc000>;
					pinctrl-single,drive-strength = <0x1000 0x1800>;
					pinctrl-single,input-schmitt = <0x0 0x30>;
					pinctrl-single,input-schmitt-enable = <0x40 0x0 0x40 0x40>;
					pinctrl-single,low-power-mode = <0x0 0x388>;
					pinctrl-single,pins = <0x37c 0x2 0x380 0x2>;
				};

				watch_a6_mfp_pins_group {
					pinctrl-single,bias-pulldown = <0x0 0xa000 0x0 0xa000>;
					pinctrl-single,bias-pullup = <0x0 0xc000 0x0 0xc000>;
					pinctrl-single,drive-strength = <0x1000 0x1800>;
					pinctrl-single,input-schmitt = <0x0 0x30>;
					pinctrl-single,input-schmitt-enable = <0x40 0x0 0x40 0x40>;
					pinctrl-single,low-power-mode = <0x0 0x388>;
					pinctrl-single,pins = <0x68 0x0 0x20c 0x0 0x210 0x0 0x2cc 0x0>;
				};
			};

			pwm@d401a000 {
				#pwm-cells = <0x2>;
				clocks = <0xb 0xd6>;
				compatible = "asr,asr-pwm";
				reg = <0xd401a000 0x10>;
				status = "disabled";
			};

			pwm@d401a400 {
				#pwm-cells = <0x2>;
				clocks = <0xb 0xd7>;
				compatible = "asr,asr-pwm";
				phandle = <0x46>;
				reg = <0xd401a400 0x10>;
				status = "okay";
			};

			pwm@d401a800 {
				#pwm-cells = <0x2>;
				clocks = <0xb 0xd9>;
				compatible = "asr,asr-pwm";
				reg = <0xd401a800 0x10>;
				status = "disabled";
			};

			pwm@d401ac00 {
				#pwm-cells = <0x2>;
				clocks = <0xb 0xda>;
				compatible = "asr,asr-pwm";
				reg = <0xd401ac00 0x10>;
				status = "disabled";
			};

			rtc@d4010000 {
				clocks = <0xb 0xd4>;
				compatible = "mrvl,mmp-rtc";
				interrupt-names = "rtc 1Hz", "rtc alarm";
				interrupts = <0x0 0x5 0x4 0x0 0x6 0x4>;
				reg = <0xd4010000 0x100>;
				status = "okay";
			};

			seh@d40b0300 {
				compatible = "asr,seh";
				interrupt-names = "CP_TIMER3";
				interrupts = <0x0 0x0 0x4>;
				reg = <0xd40b0300 0x4>;
				status = "okay";
				watchdog-type = <0x2>;
			};

			spi@d401b000 {
				#address-cells = <0x1>;
				#size-cells = <0x1>;
				asr,ssp-clock-rate = <0x18cba80>;
				asr,ssp-disable-dma;
				asr,ssp-enhancement;
				asr,ssp-id = <0x0>;
				asr,ssp-lpm-qos = <0x7>;
				clocks = <0xb 0xe1>;
				compatible = "asr,asr-spi";
				cs-gpios = <0x12 0x20 0x0>;
				dma-names = "rx", "tx";
				dmas = <0x25 0x9 0x0 0x25 0xa 0x0>;
				interrupts = <0x0 0x23 0x4>;
				reg = <0xd401b000 0x30>;
				status = "ok";

				spitp@0 {
					compatible = "jadard-spi";
					gpios = <0x12 0x7 0x0 0x12 0x8 0x0>;
					jadard,int-is-edge = <0x1>;
					jadard,irq-gpio = <0x12 0x7 0x0>;
					jadard,panel-coords = <0x0 0x2d0 0x0 0x640>;
					jadard,panel-max-points = <0xa>;
					jadard,panel-sense-nums = <0x12 0x20>;
					jadard,rst-gpio = <0x12 0x8 0x0>;
					lcm-resolution = <0x2d0 0x640>;
					reg = <0x0 0x0>;
					spi-max-frequency = <0xc65d40>;
					status = "ok";
					tpd-cfg-version = "config17";
					tpd-filter-custom-prameters = <0x0 0x0 0x0 0x0 0x0 0x0 0x0 0x0 0x0 0x0 0x0 0x0>;
					tpd-filter-custom-speed = <0x0 0x0 0x0>;
					tpd-filter-enable = <0x1>;
					tpd-filter-pixel-density = <0x92>;
					tpd-key-dim-local = <0x28 0x3d4 0x28 0x28 0x78 0x3d4 0x28 0x28 0xc8 0x3d4 0x28 0x28 0x0 0x0 0x0 0x0>;
					tpd-key-local = <0x8b 0xac 0x9e 0x0>;
					tpd-key-num = <0x3>;
					tpd-max-touch-num = <0xa>;
					tpd-resolution = <0x2d0 0x640>;
					use-tpd-button = <0x0>;
				};
			};

			spi@d401c000 {
				#address-cells = <0x1>;
				#size-cells = <0x1>;
				asr,ssp-clock-rate = <0x18cba80>;
				asr,ssp-enhancement;
				asr,ssp-id = <0x2>;
				asr,ssp-lpm-qos = <0x7>;
				clocks = <0xb 0xe2>;
				compatible = "asr,asr-spi";
				dma-names = "rx", "tx";
				dmas = <0x25 0xb 0x0 0x25 0xc 0x0>;
				interrupts = <0x0 0x24 0x4>;
				reg = <0xd401c000 0x30>;
				status = "disabled";
			};

			sulog@d40b0100 {
				clocks = <0xb 0x110>;
				compatible = "asr,sulog";
				interrupts = <0x0 0x1f 0x4>;
				reg = <0xd40b0100 0x1c>;
				status = "ok";
			};

			swjtag@d4013100 {
				clock-names = "swjtag_clk";
				clocks = <0xb 0xdf>;
				compatible = "asr,sw-jtag";
				reg = <0xd4013100 0x10>;
				status = "ok";
			};

			thermal@d4023800 {
				#thermal-sensor-cells = <0x1>;
				clock-names = "thermal_core";
				clocks = <0xb 0xde>;
				compatible = "asr,asr-thermal";
				emergent_reboot_threshold = <0x6e>;
				hot_trip_temperature = <0x157c0>;
				interrupt-names = "thermal_irq";
				interrupts = <0x0 0x28 0x4>;
				phandle = <0x3e>;
				reg = <0xd4023800 0xac>;
				status = "ok";
				temperature_offset = <0x116>;
				tsensor_en_irq = <0x1 0x1 0x1 0x1 0x1 0x0>;
				tsensor_map = <0x0 0x1 0x2 0x3 0x4 0xa>;
				tsensor_names = "local", "top", "gpu", "cpu_cluster", "cpu_core", "max";
				tsensor_num = <0x6>;
			};

			timer@d4014000 {
				asr,32k-source-id = <0x1>;
				asr,timer-apb-frequency = <0x3197500>;
				asr,timer-fastclk-frequency = <0x319750>;
				asr,timer-frequency = <0x8012>;
				asr,timer-id = <0x0>;
				clocks = <0xb 0xe3>;
				compatible = "asr,soc-timer";
				reg = <0xd4014000 0xc8>;
				status = "ok";

				counter0 {
					asr,timer-broadcast;
					asr,timer-counter-id = <0x0>;
					compatible = "asr,timer-match";
					interrupts = <0x0 0x7 0x4>;
					status = "ok";
				};
			};

			timer@d4016000 {
				asr,timer-apb-frequency = <0x3197500>;
				asr,timer-fastclk-frequency = <0x319750>;
				asr,timer-frequency = <0x8012>;
				asr,timer-id = <0x0>;
				clocks = <0xb 0xe4>;
				compatible = "asr,soc-timer1";
				reg = <0xd4016000 0xc8>;
				status = "disabled";

				counter0 {
					asr,timer-counter-id = <0x0>;
					compatible = "asr,timer-match";
					interrupts = <0x0 0xa 0x4>;
					status = "disabled";
				};
			};

			timerclk@d5001000 {
				apbc-base = <0xd4015000>;
				compatible = "asr,timer-clk";
				counter = <0x64>;
				reg = <0xd5001000 0x24>;
				status = "ok";
			};

			uart@d4017000 {
				break-abnormal;
				clock-frequency = <0xc65d40>;
				clocks = <0xb 0xdb>;
				compatible = "asr,uart";
				dma-names = "rx", "tx";
				dmas = <0x25 0x3 0x1 0x25 0x4 0x1>;
				edge-wakeup-pin = <0x36>;
				interrupts = <0x0 0x20 0x4>;
				lpm-qos = <0x7>;
				reg = <0xd4017000 0x1000>;
				status = "ok";
			};

			uart@d4017800 {
				break-abnormal;
				clock-frequency = <0xc65d40>;
				clocks = <0xb 0xdd>;
				compatible = "asr,uart";
				dma-names = "rx", "tx";
				dmas = <0x25 0x13 0x1 0x25 0x14 0x1>;
				interrupts = <0x0 0x22 0x4>;
				lpm-qos = <0x7>;
				reg = <0xd4017800 0x1000>;
				status = "ok";
			};

			uart@d4018000 {
				bluetooth-uart;
				break-abnormal;
				clock-frequency = <0xc65d40>;
				clocks = <0xb 0xdc>;
				compatible = "asr,uart";
				device-control-rts;
				dma-names = "rx", "tx";
				dmas = <0x25 0x5 0x1 0x25 0x6 0x1>;
				interrupts = <0x0 0x21 0x4>;
				lpm-qos = <0x7>;
				reg = <0xd4018000 0x1000>;
				status = "ok";
			};

			uart@d4024000 {
				break-abnormal;
				clock-frequency = <0xc65d40>;
				clocks = <0xb 0x121>;
				compatible = "asr,uart";
				dma-names = "rx", "tx";
				dmas = <0x25 0x1f 0x1 0x25 0x20 0x1>;
				interrupts = <0x0 0x33 0x4>;
				lpm-qos = <0x7>;
				reg = <0xd4024000 0x1000>;
				status = "ok";
			};

			watchdog@d4080000 {
				asr,wdt-enable-restart-handler;
				asr,wdt-enable-when-poweroff;
				clocks = <0xb 0x119>;
				compatible = "asr,soc-wdt-v0";
				interrupts = <0x0 0x13 0x4>;
				reg = <0xd4080000 0xff 0xd4050000 0x1024>;
				status = "okay";
			};
		};

		asr_crypto_engine@c0400000 {
			asr-crypto-engine-0 = <0xc0400000 0x4000>;
			compatible = "asr,crypto_engine";
			interrupts = <0x0 0x61 0x4>;
			num-engines = <0x1>;
			status = "okay";
		};

		asriommu@c0100b00 {
			#iommu-cells = <0x1>;
			clock-names = "aclk", "pclk";
			clocks = <0xb 0xf2 0xb 0x114>;
			compatible = "asr,iommu";
			interrupt-names = "v2d_iommu";
			interrupts = <0x0 0x46 0x4>;
			page-size = <0x4>;
			phandle = <0x16>;
			reg = <0x0 0xc0100b00 0x0 0x500>;
			reg-names = "v2d";
			status = "okay";
		};

		axi@d4200000 {
			#address-cells = <0x1>;
			#size-cells = <0x1>;
			compatible = "asr,axi-bus", "simple-bus";
			ranges = <0x0 0x0 0x0 0xffffffff>;
			reg = <0x0 0xd4200000 0x0 0x200000>;

			acs_mon@d4282c00 {
				compatible = "asr,asr-acs-mon";
				interrupts = <0x0 0x6b 0x4>;
				reg = <0xd4282c00 0x3d0>;
			};

			debug@d4282c00 {
				compatible = "asr,dove-axi-timeout";
				detection_modes = <0x1>;
				interrupts = <0x0 0x5c 0x4>;
				reg = <0xd4282c00 0x2d0>;
			};

			sdh@d4280000 {
				asr,aib_mmc1_io_reg = <0xd401e81c>;
				asr,apbc_asfar_reg = <0xd4015050>;
				asr,apbc_assar_reg = <0xd4015054>;
				asr,rx_dline_reg = <0x0>;
				asr,rx_tuning_limit = <0x32>;
				asr,sdh-freq = <0xc350000>;
				asr,sdh-host-caps-disable = <0x30000>;
				asr,sdh-quirks = <0x19000>;
				asr,sdh-quirks2 = <0x18000008>;
				asr,tx_delaycode = <0x32>;
				asr,tx_dline_reg = <0x0>;
				bus-width = <0x4>;
				cd-gpios = <0x12 0x7e 0x0>;
				cd-inverted;
				clock-names = "sdh-io", "sdh-core";
				clocks = <0xb 0xe8 0xb 0xe7>;
				compatible = "asr,sdh-mmc";
				interrupts = <0x0 0x53 0x4>;
				lpm-qos = <0x7>;
				no-mmc;
				no-sdio;
				pinctrl-0 = <0x19 0x1a 0x1b>;
				pinctrl-1 = <0x1c 0x1a 0x1d>;
				pinctrl-2 = <0x1e 0x1f>;
				pinctrl-names = "default", "fast", "jtag";
				reg = <0xd4280000 0x200>;
				status = "ok";
				vmmc-supply = <0x17>;
				vqmmc-supply = <0x18>;
			};

			sdh@d4280800 {
				asr,rx_dline_reg = <0x1>;
				asr,sdh-freq = <0xc350000>;
				asr,sdh-host-caps-disable = <0xc0020>;
				asr,sdh-quirks = <0x9000>;
				asr,sdh-quirks2 = <0x10000008>;
				bus-width = <0x4>;
				clock-names = "sdh-io", "sdh-core";
				clocks = <0xb 0xe9 0xb 0xe7>;
				compatible = "asr,sdh-mmc";
				interrupts = <0x0 0x54 0x4>;
				keep-power-in-suspend;
				lpm-qos = <0x7>;
				no-mmc;
				no-sd;
				non-removable;
				pinctrl-0 = <0x20 0x21>;
				pinctrl-1 = <0x22 0x23>;
				pinctrl-names = "default", "fast";
				reg = <0xd4280800 0x200>;
				status = "ok";
			};

			sdh@d4281000 {
				asr,phy_driver_sel = <0x7>;
				asr,sdh-freq = <0x165a0bc0>;
				asr,sdh-quirks = <0x9000>;
				asr,sdh-quirks2 = <0x8>;
				bus-width = <0x8>;
				clock-names = "sdh-io", "sdh-core";
				clocks = <0xb 0xea 0xb 0xe7>;
				compatible = "asr,sdh-mmc";
				fixed-emmc-driver-type = <0x1>;
				interrupts = <0x0 0x55 0x4>;
				lpm-qos = <0x7>;
				mmc-hs400-1_8v;
				mmc-hs400-enhanced-strobe;
				no-sd;
				no-sdio;
				non-removable;
				reg = <0xd4281000 0x200>;
				status = "ok";
			};
		};

		cam_sensor@0 {
			af_2v8-supply = <0x42>;
			avdd_2v8-supply = <0x43>;
			cell-index = <0x0>;
			clock-names = "cam_mclk0";
			clocks = <0xb 0x106>;
			compatible = "asr,cam-sensor";
			dovdd_1v8-supply = <0x44>;
			dphy-index = <0x0>;
			dvdd_1v2-supply = <0x45>;
			reset-gpios = <0x12 0x9 0x0>;
			status = "okay";
			twsi-index = <0x0>;
		};

		cam_sensor@1 {
			avdd_2v8-supply = <0x43>;
			cell-index = <0x1>;
			clock-names = "cam_mclk1";
			clocks = <0xb 0x107>;
			compatible = "asr,cam-sensor";
			dovdd_1v8-supply = <0x44>;
			dphy-index = <0x2>;
			dvdd_1v2-supply = <0x45>;
			pwdn-gpios = <0x12 0xd 0x0>;
			reset-gpios = <0x12 0xa 0x0>;
			status = "okay";
			twsi-index = <0x1>;
		};

		cam_sensor@2 {
			avdd_2v8-supply = <0x43>;
			cell-index = <0x2>;
			clock-names = "cam_mclk2";
			clocks = <0xb 0x108>;
			compatible = "asr,cam-sensor";
			dovdd_1v8-supply = <0x44>;
			dphy-index = <0x2>;
			dvdd_1v2-supply = <0x45>;
			reset-gpios = <0x12 0xb 0x0>;
			status = "okay";
			twsi-index = <0x1>;
		};

		ccic@d4206000 {
			asr,csiphy = <0x3a>;
			cell-index = <0x2>;
			clock-names = "csi_func", "ccic_func", "isp_ahb", "isp_axi";
			clocks = <0xb 0x105 0xb 0x100 0xb 0x101 0xb 0xfe>;
			compatible = "asr,mars11ccic";
			interrupt-names = "ipe-irq";
			interrupts = <0x0 0x43 0x4>;
			reg = <0x0 0xd4206000 0x0 0x3ff>;
			reg-names = "ccic-regs";
			status = "okay";
		};

		ccic@d420a000 {
			asr,csiphy = <0x39>;
			cell-index = <0x0>;
			clock-names = "csi_func", "ccic_func", "isp_ahb", "isp_axi";
			clocks = <0xb 0x105 0xb 0x100 0xb 0x101 0xb 0xfe>;
			compatible = "asr,mars11ccic";
			interrupt-names = "ipe-irq";
			interrupts = <0x0 0x41 0x4>;
			reg = <0x0 0xd420a000 0x0 0x3ff>;
			reg-names = "ccic-regs";
			status = "okay";
		};

		ccic@d420a800 {
			asr,csiphy = <0x3a>;
			cell-index = <0x1>;
			clock-names = "csi_func", "ccic_func", "isp_ahb", "isp_axi";
			clocks = <0xb 0x105 0xb 0x100 0xb 0x101 0xb 0xfe>;
			compatible = "asr,mars11ccic";
			interrupt-names = "ipe-irq";
			interrupts = <0x0 0x42 0x4>;
			reg = <0x0 0xd420a800 0x0 0x3ff>;
			reg-names = "ccic-regs";
			status = "okay";
		};

		cpp@C02f0000 {
			clock-names = "isp_ahb", "cpp_func", "isp_axi", "dpu_mclk";
			clocks = <0xb 0x101 0xb 0x123 0xb 0xfe 0xb 0xf2>;
			compatible = "asr,mars11cpp";
			interrupt-names = "cpp";
			interrupts = <0x0 0x44 0x4>;
			power-domains = <0x24 0x3>;
			reg = <0x0 0xc02f0000 0x0 0x7fff>;
			reg-names = "cpp";
			status = "okay";
		};

		csiphy@d4206000 {
			asr,bifmode-enable;
			cell-index = <0x2>;
			clock-names = "csi_dphy";
			clocks = <0xb 0x104>;
			compatible = "asr,csi-dphy";
			phandle = <0x3a>;
			reg = <0x0 0xd4206000 0x0 0x13f>;
			reg-names = "csiphy-regs";
			status = "okay";
		};

		csiphy@d420a000 {
			cell-index = <0x0>;
			clock-names = "csi_dphy";
			clocks = <0xb 0x102>;
			compatible = "asr,csi-dphy";
			phandle = <0x39>;
			reg = <0x0 0xd420a000 0x0 0x13f>;
			reg-names = "csiphy-regs";
			status = "okay";
		};

		csiphy@d420a800 {
			cell-index = <0x1>;
			clock-names = "csi_dphy";
			clocks = <0xb 0x103>;
			compatible = "asr,csi-dphy";
			reg = <0x0 0xd420a800 0x0 0x13f>;
			reg-names = "csiphy-regs";
			status = "disable";
		};

		dc@d4209000 {
			#address-cells = <0x2>;
			#size-cells = <0x2>;
			clock-names = "pxclk", "aclk", "busclk", "hbusclk", "ahbclk";
			clocks = <0xb 0x12b 0xb 0x12c 0xb 0x12d 0xb 0x12e 0xb 0x169>;
			compatible = "asr,dc";
			enable-qos = <0xd>;
			interrupts = <0x0 0x72 0x4>;
			lcd-panel = "lcd_gc9307_spi";
			lpm-period = <0x7d0>;
			lpm-qos = <0x7>;
			pinctrl-0 = <0x3b>;
			pinctrl-1 = <0x3c>;
			pinctrl-2 = <0x3d>;
			pinctrl-names = "qspi", "3line2lane", "4line1lane";
			reg = <0x0 0xd4209000 0x0 0x210>;
			reg-names = "dc";
			status = "ok";
			vdd_2v8-supply = <0x31>;
		};

		ddr_fc@c0000000 {
			#cooling-cells = <0x2>;
			clocks = <0xb 0xb4>;
			compatible = "asr,ddr-fc";
			enable_ipa_vmin_control;
			interrupts = <0x0 0x63 0x4>;
			reg = <0x0 0xc0000000 0x0 0x1800>;
			status = "okay";
			trfc = <0x0 0x0 0x0 0x0>;
		};

		ddraxi_mon@c0058500 {
			compatible = "asr,ddraxi-mon";
			reg = <0x0 0xc0058500 0x0 0x80>;
			status = "okay";
		};

		display-subsystem {
			compatible = "asr,saturn-le";
			hw_ver = <0x2>;
			ports = <0x2c>;
			reg = <0x0 0xc0340000 0x0 0x2a000 0x0 0xc0300300 0x0 0x40>;
		};

		dphy2@d421a800 {
			#address-cells = <0x1>;
			#size-cells = <0x0>;
			compatible = "asr,dsi2-phy";
			dev-id = <0x2>;
			ip = "asr-dphy";
			reg = <0x0 0xd421a800 0x0 0x200>;
			status = "ok";

			port@1 {
				reg = <0x1>;

				endpoint {
					phandle = <0x34>;
					remote-endpoint = <0x37>;
				};
			};
		};

		dpu_online2@c0340000 {
			asr-dpu-auto-fc;
			asr-dpu-min-mclk = <0x2710000>;
			clock-names = "pxclk", "mclk", "hclk", "escclk", "bitclk";
			clocks = <0xb 0xf0 0xb 0xf2 0xb 0xf1 0xb 0xf5 0xb 0xf6>;
			compatible = "asr,dpu-online2";
			enable-qos = <0xd>;
			interrupt-names = "ONLINE_IRQ", "OFFLINE_IRQ";
			interrupts = <0x0 0x4a 0x4 0x0 0x49 0x4>;
			ip = "asr-saturn";
			lpm-period = <0x7d0>;
			lpm-qos = <0x7>;
			memory-region = <0x2d>;
			phandle = <0x2c>;
			pipeline-id = <0x2>;
			power-domains = <0x24 0x2>;
			status = "okay";

			endpoint@0 {
				phandle = <0x35>;
				remote-endpoint = <0x2e>;
			};

			endpoint@1 {
				phandle = <0x36>;
				remote-endpoint = <0x2f>;
			};
		};

		dsi2@d421a800 {
			#address-cells = <0x1>;
			#size-cells = <0x0>;
			compatible = "asr,dsi2-host";
			dev-id = <0x2>;
			interrupts = <0x0 0x4f 0x4>;
			ip = "synopsys-dhost";
			reg = <0x0 0xd421a800 0x0 0x200>;
			status = "ok";

			panel2@0 {
				compatible = "asr,mipi-panel2";
				force-attached = "lcd_dummy_mipi";
				gpios-dc = <0x1a 0x1b>;
				gpios-reset = <0x1>;
				id = <0x2>;
				reg = <0x0>;
				status = "ok";
				tp_gc7202 = <0x32>;
				tp_icnl9911c = <0x33>;
				vdd_1v2-supply = <0x30>;
				vdd_2v8-supply = <0x31>;
			};

			ports {
				#address-cells = <0x1>;
				#size-cells = <0x0>;

				port@0 {
					reg = <0x0>;

					endpoint {
						phandle = <0x37>;
						remote-endpoint = <0x34>;
					};
				};

				port@1 {
					reg = <0x1>;

					endpoint {
						phandle = <0x2e>;
						remote-endpoint = <0x35>;
					};
				};
			};
		};

		ehci@c0900100 {
			asr,ehci-name = "mv-ehci";
			asr,extern-attr = <0x3>;
			asr,otg-force-a-bus-req;
			asr,udc-mode = <0x1>;
			clocks = <0xb 0xe6>;
			compatible = "asrci,mv-ehci";
			interrupts = <0x0 0x59 0x4>;
			phy-names = "usb-otg", "usb-phy";
			phys = <0x15 0x13>;
			reg = <0x0 0xc0900100 0x0 0x4000>;
			status = "okay";
		};

		extcon_asrci@d428287c {
			clocks = <0xb 0xe6>;
			compatible = "asrci,vbus-id";
			interrupts = <0x0 0x5a 0x4>;
			lpm-qos = <0x7>;
			phandle = <0x14>;
			reg = <0x0 0xd428287c 0x0 0x4 0x0 0xd4282918 0x0 0x4>;
			reg-names = "reg_pmuap", "pin_state";
			status = "okay";
		};

		fb@c0340000 {
			compatible = "asr,asrfb";
			interrupt-names = "ONLINE_IRQ", "OFFLINE_IRQ";
			interrupts = <0x0 0x4a 0x4 0x0 0x49 0x4>;
			reg = <0x0 0xc0340000 0x0 0x2a000>;
			status = "ok";
		};

		fm@c0883c00 {
			avdd_1v2-supply = <0x30>;
			compatible = "asr,fmradio";
			default-freq = <0x14e60>;
			reg = <0x0 0xc0883c00 0x0 0x108>;
			status = "disabled";
		};

		gpu@c0500000 {
			#cooling-cells = <0x2>;
			clock-names = "clk_mali";
			clocks = <0xb 0xeb>;
			compatible = "arm,mali-midgard", "syscon";
			dvfs-freq1 = <0x98580>;
			interrupt-names = "JOB", "MMU", "GPU";
			interrupts = <0x0 0x3c 0x4 0x0 0x3e 0x4 0x0 0x3b 0x4>;
			ipa-model = "mali-simple-power-model";
			operating-points-v2 = <0x38>;
			power-domains = <0x24 0x1>;
			poweron-freq = <0x64000>;
			reg = <0x0 0xc0500000 0x0 0x80000>;
			status = "disable";
			system-coherency = <0x1f>;

			power_model {
				compatible = "arm,mali-simple-power-model";
				dynamic-coefficient = <0x77a>;
				static-coefficient = <0x77394>;
				thermal-zone = "gpu";
				ts = <0x34cdc9 0xffff6f16 0xffffff53 0x15>;
			};
		};

		imggpu@c0500000 {
			#cooling-cells = <0x2>;
			clock-names = "clk_rgx";
			clocks = <0xb 0xeb>;
			compatible = "img,rgx";
			interrupt-names = "rgxirq";
			interrupts = <0x0 0x3b 0x4>;
			operating-points-v2 = <0x38>;
			phandle = <0x40>;
			power-domains = <0x24 0x1>;
			reg = <0x0 0xc0500000 0x0 0x100000>;
			reg-names = "rgxregs";
			status = "okay";

			power_model {
				compatible = "img,pvr-simple-power-model";
				dynamic-coefficient = <0x13>;
				static-coefficient = <0x184>;
				thermal-zone = "gpu";
				ts = <0x34cdc9 0xffff6f16 0xffffff53 0x15>;
			};
		};

		isp@C0230000 {
			clock-names = "isp_ahb", "isp_func", "isp_axi", "dpu_mclk";
			clocks = <0xb 0x101 0xb 0xff 0xb 0xfe 0xb 0xf2>;
			compatible = "asr,mars11isp";
			interrupt-names = "feisp-irq", "feisp-dma-irq";
			interrupts = <0x0 0x3f 0x4 0x0 0x45 0x4>;
			power-domains = <0x24 0x3>;
			reg = <0x0 0xc0230000 0x0 0x12700>;
			reg-names = "isp";
			status = "okay";
		};

		jpu@c02f8000 {
			clock-names = "cclk", "aclk", "iclk", "fclk", "sclk";
			clocks = <0xb 0xfa 0xb 0xf2 0xb 0xfe 0xb 0xff 0xb 0x101>;
			compatible = "chip-media, jpu";
			interrupts = <0x0 0x47 0x4>;
			jpu,cclk-default-frequency = <0x2498e580>;
			jpu,cclk-max-frequency = <0x0 0x3b9aca00>;
			jpu,cclk-min-frequency = <0x1860d840>;
			jpu,chip-id = <0x0>;
			page-size = <0x4>;
			power-domains = <0x24 0x3>;
			reg = <0x0 0xc02f8000 0x0 0x700>;
			status = "okay";
		};

		linlon-v5@c0980000 {
			#cooling-cells = <0x2>;
			clocks = <0xb 0xed>;
			compatible = "arm china,linlon-v5", "syscon";
			interrupt-parent = <0x1>;
			interrupts = <0x0 0x3a 0x4>;
			power-domains = <0x24 0x0>;
			reg = <0x0 0xc0980000 0x0 0x10000>;
			status = "okay";
		};

		lz4@d8480000 {
			clock-names = "lz4";
			clocks = <0xb 0x10d>;
			compatible = "asr,lz4";
			interrupts = <0x0 0x67 0x4>;
			lpm-qos = <0x7>;
			reg = <0x0 0xd8480000 0x0 0x80000>;
			status = "okay";
		};

		opp_table0 {
			compatible = "operating-points-v2";
			phandle = <0x38>;

			opp153600000 {
				opp-hz = <0x0 0x927c000>;
				opp-microvolt = <0xc3500>;
			};

			opp307200000 {
				opp-hz = <0x0 0x124f8000>;
				opp-microvolt = <0xc3500>;
			};

			opp491520000 {
				opp-hz = <0x0 0x1d4c0000>;
				opp-microvolt = <0xc3500>;
			};

			opp614400000 {
				opp-hz = <0x0 0x249f0000>;
				opp-microvolt = <0xdbba0>;
			};

			opp76800000 {
				opp-hz = <0x0 0x493e000>;
				opp-microvolt = <0xc3500>;
			};

			opp819200000 {
				opp-hz = <0x0 0x30d40000>;
				opp-microvolt = <0xdbba0>;
			};
		};

		otg@c0900100 {
			#phy-cells = <0x0>;
			asr,extern-attr = <0x3>;
			asr,otg-force-a-bus-req;
			asr,otg-name = "mv-otg";
			asr,udc-mode = <0x1>;
			clocks = <0xb 0xe6>;
			compatible = "asrci,mv-otg";
			extcon = <0x14>;
			lpm-qos = <0x7>;
			phandle = <0x15>;
			phy-names = "usb-phy";
			phys = <0x13>;
			reg = <0x0 0xc0900100 0x0 0x4000 0x0 0xc0940000 0x0 0x200>;
			status = "okay";
		};

		plat-cam {
			#address-cells = <0x2>;
			#size-cells = <0x2>;
			compatible = "asr,plat-cam", "simple-bus";
			status = "okay";
		};

		thermal-zones {

			cpu_cluster {
				polling-delay = <0x0>;
				polling-delay-passive = <0x0>;
				sustainable-power = <0x0>;
				thermal-sensors = <0x3e 0x3>;
			};

			cpu_core {
				polling-delay = <0x0>;
				polling-delay-passive = <0x0>;
				sustainable-power = <0x0>;
				thermal-sensors = <0x3e 0x4>;

				trips {

					cpu-trip {
						hysteresis = <0x1388>;
						temperature = <0x15f90>;
						type = "passive";
					};
				};
			};

			gpu {
				polling-delay = <0x0>;
				polling-delay-passive = <0x0>;
				sustainable-power = <0x0>;
				thermal-sensors = <0x3e 0x2>;
			};

			local {
				polling-delay = <0x0>;
				polling-delay-passive = <0x0>;
				sustainable-power = <0x0>;
				thermal-sensors = <0x3e 0x0>;
			};

			pmic-temp {
				polling-delay = <0x0>;
				polling-delay-passive = <0x0>;
				sustainable-power = <0x0>;
				thermal-sensors = <0x41 0x0>;
			};

			soc_max {
				polling-delay = <0x3e8>;
				polling-delay-passive = <0xc>;
				sustainable-power = <0x7d0>;
				thermal-sensors = <0x3e 0xa>;

				cooling-maps {

					map0 {
						contribution = <0x400>;
						cooling-device = <0x2 0xffffffff 0xffffffff 0x3 0xffffffff 0xffffffff 0x4 0xffffffff 0xffffffff 0x5 0xffffffff 0xffffffff>;
						trip = <0x3f>;
					};

					map1 {
						contribution = <0x400>;
						cooling-device = <0x40 0xffffffff 0xffffffff>;
						trip = <0x3f>;
					};
				};

				trips {

					trip-point0 {
						hysteresis = <0x1388>;
						temperature = <0x19a28>;
						type = "critical";
					};

					trip-point1 {
						hysteresis = <0x1770>;
						temperature = <0x157c0>;
						type = "hot";
					};

					trip-point2 {
						hysteresis = <0x2710>;
						phandle = <0x3f>;
						temperature = <0x13880>;
						type = "passive";
					};

					trip-point4 {
						hysteresis = <0xbb8>;
						temperature = <0xc350>;
						type = "passive";
					};
				};
			};

			top {
				polling-delay = <0x0>;
				polling-delay-passive = <0x0>;
				sustainable-power = <0x0>;
				thermal-sensors = <0x3e 0x1>;
			};
		};

		touch@0 {
			compatible = "mediatek,touch";
			phandle = <0x33>;
			status = "disabled";
		};

		udc@c0900100 {
			asr,extern-attr = <0x3>;
			asr,otg-force-a-bus-req;
			asr,udc-mode = <0x1>;
			asr,udc-name = "mv-udc";
			clocks = <0xb 0xe6>;
			compatible = "asrci,mv-udc";
			extcon = <0x14>;
			interrupts = <0x0 0x59 0x4>;
			lpm-qos = <0x7>;
			phy-names = "usb-otg", "usb-phy";
			phys = <0x15 0x13>;
			reg = <0x0 0xc0900100 0x0 0x4000 0x0 0xc0900080 0x0 0x20>;
			reg-names = "reg_cap", "reg_timer";
			status = "okay";
		};

		usbphy@c0940000 {
			#phy-cells = <0x0>;
			asr,phy-name = "mv-usb-phy";
			asr,pll-lock-bypass;
			clocks = <0xb 0xe6>;
			compatible = "asrci,usb2-phy";
			phandle = <0x13>;
			reg = <0x0 0xc0940000 0x0 0x200>;
			status = "okay";
		};

		v2d@c0100000 {
			clock-names = "v2d-io", "v2d-core";
			clocks = <0xb 0xf2 0xb 0x114>;
			compatible = "asr,asr_v2d";
			interrupts = <0x0 0x46 0x4>;
			iommus = <0x16 0x0>;
			reg = <0x0 0xc0100000 0x0 0xc00>;
			reg-names = "v2dreg";
			status = "okay";
		};

		vi@C0230000 {
			clock-names = "isp_ahb", "isp_func", "isp_axi", "dpu_mclk";
			clocks = <0xb 0x101 0xb 0xff 0xb 0xfe 0xb 0xf2>;
			compatible = "asr,mars11vi";
			interrupt-names = "feisp-irq", "feisp-dma-irq", "ccic1-irq", "ccic2-irq", "ccic3-irq";
			interrupts = <0x0 0x3f 0x4 0x0 0x45 0x4 0x0 0x41 0x4 0x0 0x43 0x4 0x0 0x43 0x4>;
			power-domains = <0x24 0x3>;
			reg = <0x0 0xc0230000 0x0 0x14000 0x0 0xd420a000 0x0 0x3ff 0x0 0xd4206000 0x0 0x3ff 0x0 0xd4206000 0x0 0x3ff>;
			reg-names = "vi", "ccic1", "ccic2", "ccic3";
			status = "okay";
		};

		wb0 {
			compatible = "asr,wb0";
			dev-id = <0x2>;
			status = "ok";

			ports {
				#address-cells = <0x1>;
				#size-cells = <0x0>;

				port@0 {
					reg = <0x0>;

					endpoint {
						phandle = <0x2f>;
						remote-endpoint = <0x36>;
					};
				};
			};
		};
	};

	usim1 {
		compatible = "asr,usim1";
		edge-wakeup-gpio = <0x50>;
		pinctrl-0 = <0x4d>;
		pinctrl-names = "default";
		status = "ok";
	};

	usim2 {
		compatible = "asr,usim2";
		edge-wakeup-gpio = <0x51>;
		status = "ok";
	};
};
